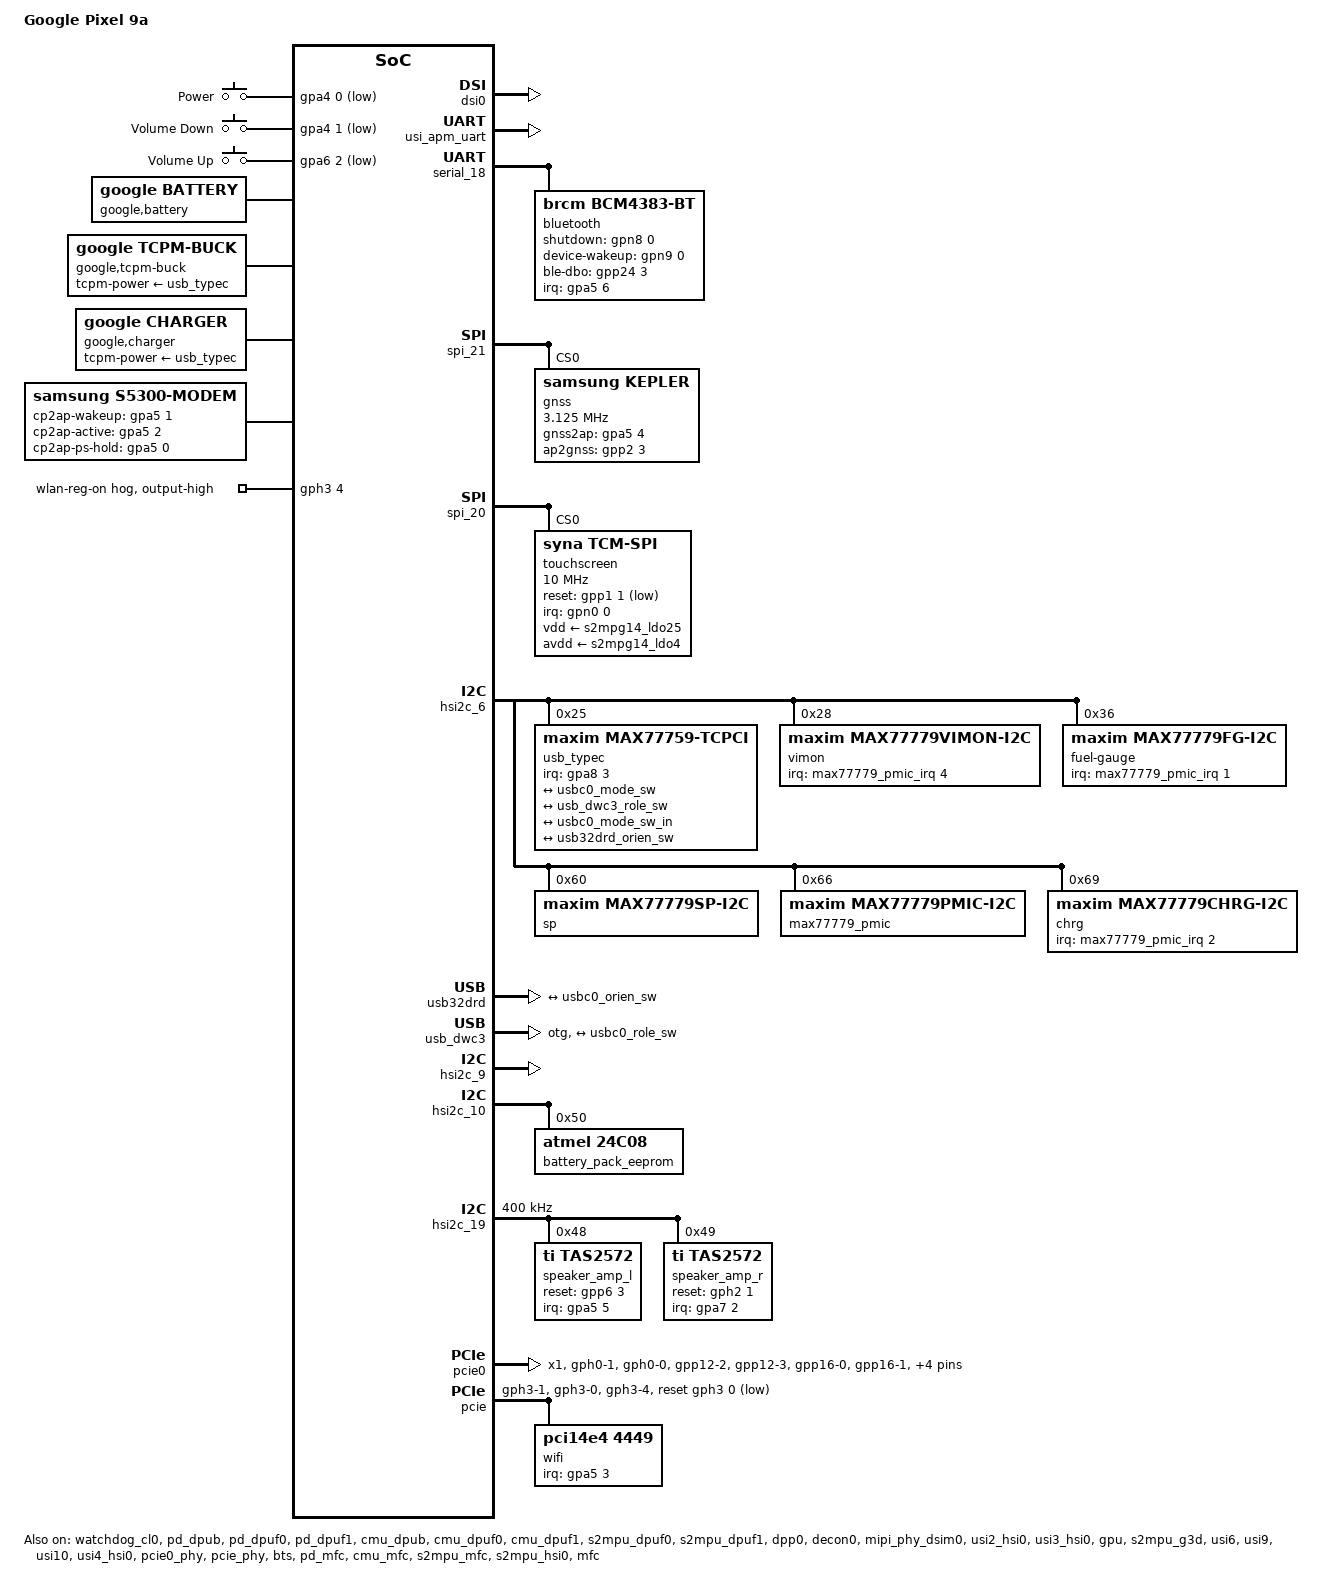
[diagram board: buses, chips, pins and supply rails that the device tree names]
// SPDX-License-Identifier: GPL-2.0-only
/*
 * Google Pixel 9a "Tegu" device tree skeleton.
 *
 * Hardware values are taken from the downstream dump in
 * ../../../../../../research/dumped.dts unless another source is named.
 */

/dts-v1/;

#include <dt-bindings/input/input.h>

#include "zumapro.dtsi"

/ {
	/*
	 * Source: model and downstream compatible strings are from
	 * research/dumped.dts:6-8.  The lowercase compatible follows the
	 * upstream Google Tensor naming convention in google.yaml.
	 */
	model = "Google Pixel 9a";
	compatible = "google,zumapro-tegu", "google,zumapro";

	aliases {
		/*
		 * Source: downstream debug UART alias is uart0/serial_0 at
		 * research/dumped.dts:5772 and 19824.
		 */
		serial0 = &serial_0;
	};

	chosen {
		/*
		 * Source: downstream bootargs select earlycon/console on
		 * 0x10870000 and ttySAC0 at research/dumped.dts:14938-14943.
		 * The empty bootargs property follows GS101 Pixel common DTS because
		 * Pixel bootloaders expect the property to exist.
		 */
		bootargs = "";
		stdout-path = "serial0:115200n8";

		framebuffer0: framebuffer-0 {
			/*
			 * Experimental bootloader framebuffer handoff. Tegu keeps
			 * the bootloader logo lit into Linux, and GS101 Pixel DTSes
			 * use 0xfac00000 for continuous splash simplefb.
			 */
			compatible = "simple-framebuffer";
			memory-region = <&cont_splash_mem>;
			width = <1080>;
			height = <2424>;
			stride = <(1080 * 4)>;
			format = "a8r8g8b8";
			status = "okay";
		};
	};

	/*
	 * Hardware buttons.  All three are plain alive-bank GPIOs with wakeup
	 * EINTs and no PMIC involvement, so they work with just gpio-keys + the
	 * pin mux below.  Source: research/dumped.dts:15219-15245 (gpio_keys)
	 * and the key-power/key-volup/key-voldown pin nodes there: power on
	 * gpa4-0 (pull-up), volume-down on gpa4-1 and volume-up on gpa6-2 (both
	 * pull-none), all in EINT function.  The downstream Android gpio flag
	 * 0x0f is its own encoding; mainline buttons are active-low (pressed =
	 * grounded), matching the in-tree exynos2200-g0s gpio-keys.
	 */
	gpio-keys {
		compatible = "gpio-keys";
		pinctrl-names = "default";
		pinctrl-0 = <&key_power &key_voldown &key_volup>;

		key-power {
			label = "Power";
			linux,code = <KEY_POWER>;
			gpios = <&gpa4 0 GPIO_ACTIVE_LOW>;
			wakeup-source;
		};

		key-voldown {
			label = "Volume Down";
			linux,code = <KEY_VOLUMEDOWN>;
			gpios = <&gpa4 1 GPIO_ACTIVE_LOW>;
			wakeup-source;
		};

		key-volup {
			label = "Volume Up";
			linux,code = <KEY_VOLUMEUP>;
			gpios = <&gpa6 2 GPIO_ACTIVE_LOW>;
			wakeup-source;
		};
	};

	decon_trigger_mask: mmio-init@19470030 {
		/*
		 * Stop the bootloader splash before the DPUF System MMUs
		 * enable translation: mask DECON0's HW trigger (TRIG_CON
		 * HW_TRIG_MASK set, HW_TRIG_EN clear) so the orphaned DPP
		 * fetch goes idle within a frame.  Letting it run into the
		 * empty default domain leaves a stalled fault on DPUF0's AXI
		 * port that wedges the interconnect on the next modeset.
		 * This freezes simplefb/fbcon; mainline owns the panel from
		 * the first modeset on.
		 */
		compatible = "linux,mmio-init-helper";
		reg = <0x0 0x19470030 0x4>;
		mask = <0x11>;
		value = <0x10>;
	};

	/*
	 * Source: RAM banks are from research/dumped.dts:20-32 and 14934-14937.
	 */
	memory@80000000 {
		device_type = "memory";
		reg = <0x0 0x80000000 0x80000000>;
	};

	memory@880000000 {
		device_type = "memory";
		reg = <0x8 0x80000000 0x80000000>;
	};

	memory@900000000 {
		device_type = "memory";
		reg = <0x9 0x00000000 0x80000000>;
	};

	memory@980000000 {
		device_type = "memory";
		reg = <0x9 0x80000000 0x80000000>;
	};

	reserved-memory {
		/*
		 * Source: static reserved-memory ranges are copied from
		 * research/dumped.dts:1292-1517.  Dynamic size-only DMA pools from
		 * the dump are intentionally omitted for this minimal initramfs tree.
		 */
		#address-cells = <2>;
		#size-cells = <1>;
		ranges;

		/*
		 * Leave one 1 MiB firmware slot below 256 MiB. All later MFC
		 * DMA allocations must be above firmware and end within its
		 * 0xf0000000-byte RISC window. This reserves device addresses
		 * only; the DMA allocator supplies the backing pages.
		 */
		mfc_firmware_iova: mfc-firmware-iova {
			iommu-addresses = <&mfc 0x00000000 0x0ff00000>,
					  <&mfc 0xfff00000 0x00100000>;
		};


		/*
		 * Source: ABL fastboot-boot log from 2026-05-24 shows ABL
		 * appends pkvm_guest_firmware@8b000000 before Linux starts.
		 * Keep the downstream range visible here, but do not compile it
		 * while booting through ABL because it overlaps the bootloader
		 * supplied node.
		 */
#if 0
		pkvm_guest_firmware: pkvm-guest-firmware@8b000000 {
			/* Source: research/dumped.dts:1298-1302. */
			reg = <0x0 0x8b000000 0x100000>;
			no-map;
		};
#endif

		ect_reserved: ect@90000000 {
			/* Source: research/dumped.dts:1319-1322. */
			reg = <0x0 0x90000000 0x60000>;
		};

		gsa_reserved: gsa@90200000 {
			/* Source: research/dumped.dts:1325-1328. */
			reg = <0x0 0x90200000 0x3ff000>;
			no-map;
		};

		gsa_reserved_2: gsa@905ff000 {
			/* Source: research/dumped.dts:1331-1334. */
			reg = <0x0 0x905ff000 0x1000>;
			no-map;
		};

		gxp_scratchpad_reserved: gxp-scratchpad@91300000 {
			/* Source: research/dumped.dts:1337-1340. */
			reg = <0x0 0x91300000 0x60000>;
			no-map;
		};

		iif_wait_table_reserved: iif-wait-table@91360000 {
			/* Source: research/dumped.dts:1343-1346. */
			reg = <0x0 0x91360000 0x20000>;
			no-map;
		};

		iif_signal_table_reserved: iif-signal-table@91380000 {
			/* Source: research/dumped.dts:1349-1352. */
			reg = <0x0 0x91380000 0x20000>;
			no-map;
		};

		gxp_secure_data_reserved: gxp-secure-data@91400000 {
			/* Source: research/dumped.dts:1355-1358. */
			reg = <0x0 0x91400000 0x900000>;
			no-map;
		};

		gxp_fw_reserved: gxp-fw@91d00000 {
			/* Source: research/dumped.dts:1361-1364. */
			reg = <0x0 0x91d00000 0x300000>;
			no-map;
		};

		gxp_mcu_fw_reserved: gxp-mcu-fw@92000000 {
			/* Source: research/dumped.dts:1367-1370. */
			reg = <0x0 0x92000000 0x400000>;
			no-map;
		};

		tpu_fw_reserved: tpu-fw@92e00000 {
			/* Source: research/dumped.dts:1373-1376. */
			reg = <0x0 0x92e00000 0x1200000>;
			no-map;
		};

		aoc_reserved: aoc@94000000 {
			/* Source: research/dumped.dts:1379-1382. */
			reg = <0x0 0x94000000 0x3000000>;
			no-map;
		};

		cont_splash_mem: splash@fac00000 {
			/*
			 * Experimental simplefb backing store. 0xfac00000 matches
			 * the GS101 continuous-splash address; no explicit Tegu
			 * downstream reserved-memory node exists in dumped.dts.
			 */
			reg = <0x0 0xfac00000 (1080 * 2424 * 4)>;
			no-map;
		};

		xhci_dma_buffer_reserved: xhci-dma-buffer@17bb5000 {
			/* Source: research/dumped.dts:1508-1512. */
			reg = <0x0 0x17bb5000 0xb000>;
			no-map;
		};

		xhci_dma_reserved: xhci-dma@17bc0000 {
			/* Source: research/dumped.dts:1515-1519. */
			reg = <0x0 0x17bc0000 0x40000>;
			no-map;
		};

		xhci_dma_dram_reserved: xhci-dma-dram@97000000 {
			/* Source: research/dumped.dts:1522-1526. */
			reg = <0x0 0x97000000 0x400000>;
			no-map;
		};

		/*
		 * Source: ABL fastboot-boot log from 2026-05-24 shows ABL
		 * appends sec_dram@b6200000 before Linux starts.  Keep the
		 * downstream range visible here, but do not compile it while
		 * booting through ABL because it overlaps the bootloader supplied
		 * node.
		 */
#if 0
		sec_dram_reserved: sec-dram@b6200000 {
			/* Source: research/dumped.dts:1314-1317. */
			reg = <0x0 0xb6200000 0x9e00000>;
			no-map;
		};
#endif

		seclog_reserved: seclog@c3000000 {
			/* Source: research/dumped.dts:1502-1505. */
			reg = <0x0 0xc3000000 0x80000>;
		};

		header_reserved: header@d8100000 {
			/* Source: research/dumped.dts:1438-1441. */
			reg = <0x0 0xd8100000 0x10000>;
			no-map;
		};

		log_kevents_reserved: log-kevents@d8110000 {
			/* Source: research/dumped.dts:1444-1447. */
			reg = <0x0 0xd8110000 0x700000>;
			no-map;
		};

		log_bcm_reserved: log-bcm@dd610000 {
			/* Source: research/dumped.dts:1450-1454. */
			reg = <0x0 0xdd610000 0x400000>;
			no-map;
		};

		log_s2d_reserved: log-s2d@d8810000 {
			/* Source: research/dumped.dts:1456-1459. */
			reg = <0x0 0xd8810000 0x1800000>;
			no-map;
		};

		log_array_reset_reserved: log-array-reset@da010000 {
			/* Source: research/dumped.dts:1462-1465. */
			reg = <0x0 0xda010000 0xa00000>;
			no-map;
		};

		log_array_panic_reserved: log-array-panic@daa10000 {
			/* Source: research/dumped.dts:1469-1473. */
			reg = <0x0 0xdaa10000 0xa00000>;
			no-map;
		};

		log_slcdump_reserved: log-slcdump@db410000 {
			/* Source: research/dumped.dts:1476-1480. */
			reg = <0x0 0xdb410000 0x1100000>;
			no-map;
		};

		log_preslcdump_reserved: log-preslcdump@dc510000 {
			/* Source: research/dumped.dts:1483-1487. */
			reg = <0x0 0xdc510000 0x1100000>;
			no-map;
		};

		log_itmon_reserved: log-itmon@dda10000 {
			/* Source: research/dumped.dts:1493-1496. */
			reg = <0x0 0xdda10000 0x10000>;
			no-map;
		};

		log_s2d_extract_reserved: log-s2d-extract@dda20000 {
			/* Source: research/dumped.dts:1499-1502. */
			reg = <0x0 0xdda20000 0x600000>;
			no-map;
		};

		/*
		 * Source: ABL fastboot-boot log from 2026-05-24 shows ABL
		 * appends sec_pt@e0000000 before Linux starts.  Keep the
		 * downstream range visible here, but do not compile it while
		 * booting through ABL because it overlaps the bootloader supplied
		 * node.
		 */
#if 0
		sec_pt_reserved: sec-pt@e0000000 {
			/* Source: research/dumped.dts:1309-1312. */
			reg = <0x0 0xe0000000 0x3800000>;
			no-map;
		};
#endif

		cp_rmem_1_reserved: cp-rmem-1@e8000000 {
			/*
			 * Source: research/dumped.dts:1424-1428.  The PKTPROC
			 * DL/UL data rings + buffers; the CP addresses it at
			 * pktproc_cp_base 0x20000000 and self-translates to this
			 * AP-phys before the TLP, so no AP-side window is needed
			 * (docs/subsystems/modem/reference/pktproc-plan.md "Risk #1").  no-map for the
			 * same reason as cp_rmem: the driver maps it non-cached
			 * and the CP DMAs into it (HSI1 IO-coherency is not set
			 * up on mainline).
			 */
			reg = <0x0 0xe8000000 0x2000000>;
			no-map;
		};

		cp_aoc_rmem_reserved: cp-aoc-rmem@197fd000 {
			/* Source: research/dumped.dts:1431-1435. */
			reg = <0x0 0x197fd000 0x3000>;
		};

		cp_rmem_reserved: cp-rmem@ea400000 {
			/*
			 * Source: research/dumped.dts:1410-1414.  no-map so the
			 * modem driver can map it non-cached: the CP reads the
			 * staged boot image and runs the IPC queues in here by
			 * PCIe bus-mastering, and HSI1 IO-coherency is not set
			 * up on mainline.
			 */
			reg = <0x0 0xea400000 0xc00000>;
			no-map;
		};

		cp_msi_rmem_reserved: cp-msi-rmem@f6200000 {
			/*
			 * Source: research/dumped.dts:1417-1421.  no-map for
			 * the same reason: the CP DMA-writes its boot progress
			 * above the MSI termination address in this page.
			 */
			reg = <0x0 0xf6200000 0x1000>;
			no-map;
		};

		abl_reserved: abl@f8800000 {
			/* Source: research/dumped.dts:1304-1307. */
			reg = <0x0 0xf8800000 0x1000000>;
			no-map;
		};

		dss_log_reserved: dss-log@fd3f0000 {
			/* Source: research/dumped.dts:1385-1388. */
			reg = <0x0 0xfd3f0000 0xe000>;
			no-map;
		};

		/*
		 * Source: ABL fastboot-boot log from 2026-05-24 shows ABL
		 * appends debug_kinfo_reserved@fd3fe000 before Linux starts.
		 * Keep the downstream range visible here, but do not compile it
		 * while booting through ABL because it overlaps the bootloader
		 * supplied node.
		 */
#if 0
		debug_kinfo_reserved: debug-kinfo@fd3fe000 {
			/* Source: research/dumped.dts:1391-1394. */
			reg = <0x0 0xfd3fe000 0x1000>;
			no-map;
		};
#endif

		ramoops_reserved: ramoops@fd3ff000 {
			/*
			 * Source: research/dumped.dts:1397-1401, with the pmsg
			 * zone traded for dmesg records.  Downstream splits the
			 * 4 MiB into 2 MiB console + 2 MiB pmsg and carves no
			 * record zone at all, because the pmsg consumer is
			 * Android's logd and its panic post-mortems come from
			 * debug-snapshot; neither exists here, so pmsg would be
			 * 2 MiB that nothing ever reads.  The dmesg zones take
			 * whatever console and pmsg leave (ram.c: dump_mem_sz =
			 * size - console - ftrace - pmsg), hence 8 records here.
			 * Console gets the larger share: a lockup that stops
			 * printing never reaches kmsg_dump, so the console ring
			 * is the only thing that will hold its last moments.
			 */
			compatible = "ramoops";
			reg = <0x0 0xfd3ff000 0x400000>;
			console-size = <0x300000>;
			record-size = <0x20000>;
		};

		bldr_log_reserved: bldr-log@fd800000 {
			/* Source: research/dumped.dts:1404-1407. */
			reg = <0x0 0xfd800000 0x100000>;
			no-map;
		};
	};

	/*
	 * Where GBMS finds the battery pack EEPROM.  gbms_storage locates this
	 * by node name -- of_find_node_by_name(NULL, "google_bms") -- so the
	 * name is the binding and there is no compatible; it reads the pack's
	 * records through the nvmem device named here, which is the ordinary
	 * at24 on i2c-10 (research/dumped.dts:20030).
	 *
	 * Deliberately no "google,lotr-version", matching downstream.  Absent,
	 * the layout version defaults to GBMS_LOTR_DEFAULT (0xff), and
	 * gbms_lotr_update() converts only when the *requested* version is V1 or
	 * V2 -- so the default cannot reach either migration whatever the pack
	 * itself holds.  That matters because both migrations are destructive to
	 * records the Android slot also reads: V1 shifts 900 bytes of history up
	 * by six and zeroes five bytes at 0x5e, V2 writes 0xff over 0x3e2..0x3fe.
	 *
	 * The EEPROM node's "read-only" is a second guard, but not where it
	 * looks: nvmem_device_write() does not consult nvmem->read_only at all.
	 * What refuses the write is at24, which leaves write_max at 0 for a
	 * read-only part, so at24_adjust_write_count() clamps the count to zero
	 * and regmap returns -EINVAL before any byte is sent.  Effective, and
	 * thinner than it sounds -- it rests on regmap rejecting a zero-length
	 * write rather than looping.
	 */
	google_bms {
		nvmem = <&battery_pack_eeprom>;
		nvmem-names = "bms-pack-eeprom";
		google,bee-name = "bms-pack-eeprom";
	};

	/*
	 * The battery layer.  It aggregates the gauge and the charger into the
	 * "battery" power supply userspace sees, runs the multi-tier charge
	 * table below, and is where charge_limit lives.
	 *
	 * The table is the point of the node.  chg-cc-limits is a 6x5 matrix of
	 * percent-of-design-capacity, indexed by the temperature bands in
	 * chg-temp-limits (0/10/20/44/46/48/55 degC) and the float-voltage
	 * tiers in chg-cv-limits (4.20/4.25/4.30/4.35/4.50 V), and scaled by
	 * chg-battery-capacity -- 5000 mAh, which takes priority over the
	 * gauge's 5110 mAh CHARGE_FULL_DESIGN.  So the peak cell, 100% between
	 * 20 and 44 degC below 4.35 V, is 5.0 A, and the coldest and hottest
	 * bands fall to 0.5 A or refuse to charge at all.
	 *
	 * google,eeprom-pairing is deliberately dropped.  It is the one part of
	 * this layer that establishes identity on the pack: when it reads an
	 * unpaired battery it writes an MD5 of the device serial and the pack's
	 * manufacturer record into the pack's DINF tag.  This pack is already
	 * paired, by the Android slot that shares the EEPROM, so the branch
	 * that fires here would be the mismatch one -- and the pairing state is
	 * reported in sysfs and gates no charging decision, so nothing is lost
	 * by not asking.
	 *
	 * What is *not* avoidable is that this node makes the kernel a routine
	 * writer of that shared pack: batt_cycle_count_update() runs from the
	 * battery work loop and stores the SoC-residency bins to BCNT.  That is
	 * the same record, at the same offsets, that the other slot maintains
	 * -- the pack reads as layout v0, which is the layout the driver's
	 * default selects -- so the two agree on where it is, and each keeps
	 * its own tally of the same quantity.
	 */
	google,battery {
		compatible = "google,battery";
		google,fg-psy-name = "max77779fg";

		google,chg-battery-capacity = <0x1388>;
		google,chg-temp-limits = <0x00 0x64 0xc8 0x1b8 0x1cc 0x1e0 0x226>;
		google,chg-cv-limits = <0x401640 0x40d990 0x419ce0 0x426030 0x44aa20>;
		google,chg-cc-limits = <
			0x1e 0x0a 0x0a 0x00 0x00
			0x32 0x1e 0x1e 0x1e 0x1e
			0x64 0x64 0x64 0x64 0x32
			0x5a 0x5a 0x5a 0x5a 0x32
			0x32 0x32 0x32 0x00 0x00
			0x1e 0x00 0x00 0x00 0x00>;
		google,chg-topoff-limits = <0xfa 0xfa 0xfa 0x1f4 0x1f4 0x1f4>;

		google,fv-uv-resolution = <0x2710>;
		google,fv-uv-margin-dpct = <0x401>;
		google,cv-range-accuracy = <0x4e20>;
		google,cv-otv-margin = <0x2ee0>;
		google,cv-debounce-cnt = <0x03>;
		google,cv-tier-ov-cnt = <0x0a>;
		google,cv-tier-switch-cnt = <0x03>;
		google,chg-rest-rate = <0x0f>;
		google,chg-rest-soc = <0x50>;
		google,bd-trickle-recharge-soc = <0x50>;

		/* Time-to-full estimation. */
		google,ttf-temp-idx = <0x02>;
		google,ttf-adapter = <0x1194>;
		google,ttf-soc-table = <0x3f 0x43 0x47 0x4b 0x55 0x5b 0x61 0x64>;
		google,ttf-elap-table = <0x27 0x2a 0x30 0x37 0x49 0x73 0xcb 0x52>;
		google,ttf-tier-table = <0x00 0x3e 0x4b>;
		google,ttf-report-max-ratio = <0x00>;

		/* Battery health: record thresholds and BHI tuning. */
		google,temp-record-thr = <0x12c 0x15e 0x190>;
		google,soc-record-thr = <0x5a 0x5a 0x5f>;
		google,bhi-status-marginal = <0x4f>;
		google,bhi-status-need-rep = <0x4f>;
		google,bhi-cycle-grace = <0x64>;
		google,bhi-algo-ver = <0x03>;

		/*
		 * Age-adjusted charging.  AACR derates the table's capacity by
		 * cycle count and AAFV lowers the float voltage; both read the
		 * cycle count from the pack the other slot has been filling in,
		 * so they start from this battery's real age rather than from
		 * zero.  The aact-* tables are the server-updatable variants --
		 * carried so the node matches downstream, but inert here,
		 * because gbms_init_chg_table() uses them only once something
		 * has actually pushed an update.
		 */
		google,aacr-config = <0x01>;
		google,aafv-config = <0x01>;
		google,aacr-algo = <0x03>;
		google,aacr-cliff-capacity-rate = <0x50>;
		google,aacr-cycle-max = <0x3e8>;
		google,enable-switch-chg-profile;
		google,aact-cv-limits = <0x401640 0x40d990 0x419ce0 0x426030 0x44aa20>;
		google,aact-temp-limits = <0x00 0x64 0xc8 0x1b8 0x1cc 0x1e0 0x226>;
		google,chg-aact-ecc = <0x00 0x12c 0x3e8>;
		google,aact-cc-limits = <
			0x1e 0x0a 0x0a 0x00 0x00
			0x32 0x1e 0x1e 0x1e 0x1e
			0x64 0x64 0x64 0x64 0x32
			0x5a 0x5a 0x5a 0x5a 0x32
			0x32 0x32 0x32 0x00 0x00
			0x1e 0x00 0x00 0x00 0x00
			0x1e 0x0a 0x0a 0x00 0x00
			0x32 0x1e 0x1e 0x1e 0x1e
			0x5f 0x5f 0x5f 0x5f 0x32
			0x5a 0x5a 0x5a 0x5a 0x32
			0x32 0x32 0x32 0x00 0x00
			0x1e 0x00 0x00 0x00 0x00
			0x1e 0x0a 0x0a 0x00 0x00
			0x32 0x1e 0x1e 0x1e 0x1e
			0x5a 0x5a 0x5a 0x5a 0x32
			0x5a 0x5a 0x5a 0x5a 0x32
			0x32 0x32 0x32 0x00 0x00
			0x1e 0x00 0x00 0x00 0x00>;

		/*
		 * Battery virtual sensors.  Both thermal registrations are
		 * non-fatal -- the driver logs and carries on -- so these cost
		 * nothing while no thermal zone references them.
		 */
		google,batt-vs-tz-name = "batt_vs";
		#thermal-sensor-cells = <0x00>;
		#cooling-cells = <0x02>;

		/* Per-cell age references, keyed by the pack's battery ID. */
		google,batt-id-1-atl {
			google,batt-id = <0x01>;
			google,aacr-ref-cycles = <0x257 0x258 0x3e8>;
			google,aacr-ref-fade10 = <0x00 0x64 0x64>;
			google,aafv-ref-cycles = <0xc8 0x190 0x258 0x320 0x3e8 0x3e9>;
			google,aafv-ref-offset = <0x00 0x14 0x28 0x3c 0x50 0x64>;
			google,aacc-chg-temp = <0x00 0x226>;
			google,aacc-chg-weights = <
				0x64 0x64 0x64 0x64 0x64 0x64 0x64 0x64 0x64 0x64
				0x00 0x00 0x00 0x00 0x00 0x00 0x00 0x00 0x00 0x00
				0x00 0x00 0x00 0x00 0x00 0x00 0x00 0x00 0x00 0x00
				0x00 0x00 0x00 0x00 0x00 0x00 0x00 0x00 0x00 0x00
				0x00 0x00 0x00 0x00 0x00 0x00 0x00 0x00 0x00 0x00
				0x00 0x00 0x00 0x00 0x00 0x00 0x00 0x00 0x00 0x00
				0x00 0x00 0x00 0x00 0x00 0x00 0x00 0x00 0x00 0x00
				0x00 0x00 0x00 0x00 0x00 0x00 0x00 0x00 0x00 0x00
				0x00 0x00 0x00 0x00 0x00 0x00 0x00 0x00 0x00 0x00
				0x00 0x00 0x00 0x00 0x00 0x00 0x00 0x00 0x00 0x00>;
		};

		google,batt-id-4-lwn {
			google,batt-id = <0x04>;
			google,aacr-ref-cycles = <0x257 0x258 0x3e8>;
			google,aacr-ref-fade10 = <0x00 0x64 0x64>;
			google,aafv-ref-cycles = <0xc8 0x190 0x258 0x320 0x3e8 0x3e9>;
			google,aafv-ref-offset = <0x00 0x14 0x28 0x3c 0x50 0x64>;
			google,aacc-chg-temp = <0x00 0x226>;
			google,aacc-chg-weights = <
				0x64 0x64 0x64 0x64 0x64 0x64 0x64 0x64 0x64 0x64
				0x00 0x00 0x00 0x00 0x00 0x00 0x00 0x00 0x00 0x00
				0x00 0x00 0x00 0x00 0x00 0x00 0x00 0x00 0x00 0x00
				0x00 0x00 0x00 0x00 0x00 0x00 0x00 0x00 0x00 0x00
				0x00 0x00 0x00 0x00 0x00 0x00 0x00 0x00 0x00 0x00
				0x00 0x00 0x00 0x00 0x00 0x00 0x00 0x00 0x00 0x00
				0x00 0x00 0x00 0x00 0x00 0x00 0x00 0x00 0x00 0x00
				0x00 0x00 0x00 0x00 0x00 0x00 0x00 0x00 0x00 0x00
				0x00 0x00 0x00 0x00 0x00 0x00 0x00 0x00 0x00 0x00
				0x00 0x00 0x00 0x00 0x00 0x00 0x00 0x00 0x00 0x00>;
		};
	};

	/*
	 * The charging policy layer, and the last of the stack.  It runs the
	 * multi CC-CV step charge over google_battery's table, applies the
	 * charge stop and start levels, and owns the battery defender that
	 * pauses charging when the pack sits hot and full.
	 *
	 * Three of the four supplies it names differ from the vendor's, and
	 * each difference removes a layer rather than adding one:
	 *
	 *   - chg-power-supply names the MAX77779 directly rather than "gccd".
	 *     google_ccd exists to present several wired chargers as one, and
	 *     this board describes a single one; the six properties this layer
	 *     asks of a charger -- constant charge current and voltage, the
	 *     termination current, taper control, charging-enabled and the
	 *     GBMS charger state -- are all answered by max77779_charger
	 *     itself.
	 *   - usb-power-supply is omitted entirely rather than pointed at the
	 *     TCPM source supply.  This layer asks a USB supply for PRESENT,
	 *     which TCPM deliberately does not implement -- naming it would
	 *     make every read return -EINVAL, which the caller stores as the
	 *     value, leaving "present" permanently true and the disconnect
	 *     path unreachable.  Left unnamed, the driver substitutes its
	 *     online state, which it reads from the TCPM supply named below
	 *     anyway.  So the vendor's usb_psy.c buys nothing here.
	 *   - wlc-power-supply is omitted with the rest of the wireless
	 *     properties.  The P9222 receiver has no driver here, so nothing
	 *     registers a "wireless" supply; the lookup is optional and the
	 *     pad still charges, because its power reaches the MAX77779's WCIN
	 *     input and is reported by that driver's own "dc" supply.
	 *
	 * tcpm-power-supply stays a phandle to the TCPC, which is how the PPS
	 * code reaches the partner's advertised source capabilities.
	 */
	/*
	 * The buck-mode ballot mainline's Type-C stack does not cast.
	 *
	 * The charger arbitrates its operating mode from the CHARGER_MODE
	 * election, and google_charger's vote asks only for a charge current
	 * -- it never says that an input is attached.  The vote that does is
	 * cast by the vendor's own port controller driver on sink attach, and
	 * this board runs mainline's tcpci_maxim instead, which knows nothing
	 * about it.  Without the ballot the charger resolves to all-off and
	 * switches charging off entirely, so this is not optional.
	 *
	 * It watches the ONLINE property of the supply named here, which is
	 * the sink state TCPM already tracks.
	 */
	google,tcpm-buck {
		compatible = "google,tcpm-buck";
		google,tcpm-power-supply = <&usb_typec>;
	};

	google,charger {
		compatible = "google,charger";
		#cooling-cells = <0x02>;

		google,chg-power-supply = "main-charger";
		google,bat-power-supply = "battery";
		google,tcpm-power-supply = <&usb_typec>;

		google,fv-max-uv = <0x47b760>;
		google,chg-termination-5v;
		google,chg-taper-last-tier;

		/*
		 * Battery defender: stop charging and drain back when the pack
		 * has been hot and near full for long enough, and resume when
		 * it cools or falls back.
		 */
		google,bd-temp-enable;
		google,bd-trigger-time = <0x5460>;
		google,bd-trigger-temp = <0x15e>;
		google,bd-trigger-voltage = <0x4127b0>;
		google,bd-recharge-voltage = <0x40d990>;
		google,bd-drainto-soc = <0x50>;
		google,bd-recharge-soc = <0x4f>;
		google,bd-resume-abs-temp = <0x118>;
		google,bd-resume-soc = <0x32>;
		google,bd-resume-time = <0x3840>;
		google,bd-resume-temp = <0x122>;

		/* Charge-current ceilings for the thermal cooling device. */
		google,thermal-mitigation = <0x4c4b40 0x498c20 0x46cd00 0x440de0
			0x414ec0 0x3e8fa0 0x3bd080 0x391160 0x365240 0x339320
			0x30d400 0x2e14e0 0x2b55c0 0x2896a0 0x25d780 0x231860
			0x205940 0x1d9a20 0x1adb00 0x181be0 0x155cc0 0x129da0
			0xfde80 0xd1f60 0xa6040 0x7a120>;
		google,thermal-mitigation-budgets = <0x389c30 0x367d38 0x348938
			0x324ee8 0x303f90 0x2e6300 0x2c8670 0x2ae090 0x293e98
			0x27a470 0x260a48 0x238d90 0x2191c0 0x1fbd00 0x1e0780
			0x1c7528 0x1b0210 0x19b220 0x185678 0x16fad0 0x1608a0
			0x151670 0x149d58 0x142440 0x136ca8 0x12b128>;
		google,thermal-stats-lvl-map = <0x00 0x02 0x05 0x08 0x0b>;
	};
};

&watchdog_cl0 {
	/*
	 * Source: downstream enables watchdog_cl0 implicitly in
	 * research/dumped.dts:15248-15257.  Cluster 1 remains disabled until the
	 * downstream use_multistage_wdt behavior at dumped.dts:15268 is modeled.
	 */
	status = "okay";
};

&pd_dpub {
	status = "okay";
};

&pd_dpuf0 {
	status = "okay";
};

&pd_dpuf1 {
	status = "okay";
};

&cmu_dpub {
	status = "okay";
};

&cmu_dpuf0 {
	status = "okay";
};

&cmu_dpuf1 {
	status = "okay";
};

/*
 * DPU fetch path: framebuffer scanout through DPP0 with the DPUF System MMUs
 * translating.  The always-on display power domains must be enabled so the
 * SysMMU single-domain auto-attach can find its provider.
 *
 * Enabling translation orphans the bootloader splash: its DPP fetch faults
 * against the empty default domain as soon as DECON probes.  The first
 * mainline modeset stops and reprograms the pipeline anyway.
 */
&pd_dpub {
	status = "okay";
};

&pd_dpuf0 {
	status = "okay";
};

&pd_dpuf1 {
	status = "okay";
};

&iommu_group_dpu {
	status = "okay";
};

/* Reopened on every DPUF domain power-on, before its System MMU resumes. */
&s2mpu_dpuf0 {
	status = "okay";
};

&s2mpu_dpuf1 {
	status = "okay";
};

&sysmmu_dpuf0 {
	status = "okay";
};

&sysmmu_dpuf1 {
	status = "okay";
};

&dpp0 {
	status = "okay";
};

&decon0 {
	status = "okay";
};

/*
 * Transmit-side probe.  Keep this before enabling real scanout: DSIM/DPHY/panel
 * may bind and attach, but link/PHY programming should remain gated on DRM
 * bridge enable or host transfers.
 */
&sysreg_dpub {
	status = "okay";
};

&mipi_phy_dsim0 {
	status = "okay";
};

&dsi0 {
	status = "okay";

	panel@0 {
		status = "okay";
	};
};

/*
 * S2MPG14 main PMIC, reached over ACPM IPC channel 2 with PMIC select 0.
 * Source: downstream zuma-pmic.dtsi s2mpg14mfd (acpm-ipc-channel = <2>,
 * acpm-speedy-channel = <0>, IRQ = INTCOMB_VGPIO2AP_ALIVE = GIC SPI 74).
 * The interrupt is the APM vGPIO combiner output; the mainline driver
 * does not request it yet (no combiner driver), it only has to resolve.
 *
 * Only the touchscreen rails are described, and deliberately WITHOUT
 * voltage constraints: the driver is enable-only, the bootloader leaves
 * the voltage selectors at the correct values (L4M reads 0x3c, L25M 0x2c
 * before the downstream kernel touches them), and the downstream kernel
 * also only ever flips the enable bit (UPDATE val=0x80 mask=0x80) —
 * hardware-verified in research/tracing/acpm-boot-rail-snapshot.md.
 * Downstream constraints, for reference only: L4M 2.5-3.3 V (TS1_AVDD),
 * L25M 1.6-1.95 V (TS1_DVDD).  Keep new rails equally minimal; a wrong
 * voltage constraint here is the one thing that can genuinely damage
 * hardware.
 */
&acpm_ipc {
	pmic {
		compatible = "samsung,s2mpg14-pmic";
		/*
		 * The PMIC has no interrupt wire: it raises an in-band I3C
		 * interrupt which the APM forwards through the vGPIO-to-AP
		 * combiner, and the combiner drives this GIC line.
		 */
		interrupts = <GIC_SPI 74 IRQ_TYPE_LEVEL_HIGH 0>;
		samsung,vgpio2ap-syscon = <&sysreg_vgpio2ap>;
		wakeup-source;

		regulators {
			s2mpg14_ldo4: ldo4m {
				regulator-name = "L4M_TS1_AVDD";
			};

			s2mpg14_ldo25: ldo25m {
				regulator-name = "L25M_TS1_DVDD";
			};
		};

		/*
		 * On-device power metering, read-only.  Channel -> rail mux is
		 * the authoritative tegu ODPM assignment from
		 * research/dumped.dts (mux codes are the S2MPG14 muxsel values,
		 * BUCK1..9 = 0x01..0x09).  Channels 0-8 are the internal buck
		 * rails; 9-11 are the external (VSEN) rails (schematic
		 * VSYS_PWR_DISPLAY/CAMERA/RFFE) sensed across an off-chip shunt.
		 */
		meter {
			compatible = "samsung,s2mpg14-meter";
			#address-cells = <1>;
			#size-cells = <0>;

			channel@0 {
				reg = <0>;
				samsung,muxsel = <0x01>;
				label = "VDD_MIF";
			};
			channel@1 {
				reg = <1>;
				samsung,muxsel = <0x02>;
				label = "VDD_CPUCL1_MID";
			};
			channel@2 {
				reg = <2>;
				samsung,muxsel = <0x03>;
				label = "VDD_CPUCL2_BIG";
			};
			channel@3 {
				reg = <3>;
				samsung,muxsel = <0x04>;
				label = "VDD_CPUCL0_LITTLE";
			};
			channel@4 {
				reg = <4>;
				samsung,muxsel = <0x05>;
				label = "VDD_INT";
			};
			channel@5 {
				reg = <5>;
				samsung,muxsel = <0x06>;
				label = "LLDO1";
			};
			channel@6 {
				reg = <6>;
				samsung,muxsel = <0x07>;
				label = "VDD_TPU";
			};
			channel@7 {
				reg = <7>;
				samsung,muxsel = <0x08>;
				label = "LLDO2";
			};
			channel@8 {
				reg = <8>;
				samsung,muxsel = <0x09>;
				label = "VDD_CPUCL1_M";
			};

			/* External (VSEN) rails: VSYS drop across an off-chip shunt. */
			channel@9 {
				reg = <9>;
				samsung,muxsel = <0x5c>;
				shunt-resistor-micro-ohms = <5000>;
				label = "VSYS_PWR_DISPLAY";
			};
			channel@10 {
				reg = <10>;
				samsung,muxsel = <0x5d>;
				shunt-resistor-micro-ohms = <5000>;
				label = "VSYS_PWR_CAMERA";
			};
			channel@11 {
				reg = <11>;
				samsung,muxsel = <0x5e>;
				shunt-resistor-micro-ohms = <5000>;
				label = "VSYS_PWR_RFFE";
			};
		};
	};
};

/*
 * S2MPG15 sub PMIC, reached over ACPM IPC channel 2 with PMIC select 1
 * (mirroring the s2mpg10/s2mpg11 main/sub pair).  Source: downstream
 * zuma-pmic.dtsi s2mpg15mfd (acpm-speedy-channel = <1>).  Only the
 * read-only ODPM power meter is described; no regulators are claimed.
 *
 * Channel -> rail mux follows the tegu ODPM assignment from
 * research/dumped.dts.  Internal rails use the S2MPG15 muxsel values
 * (BUCKnS = 0x0n, LDOnS = 0x20 + n); two external rails (MODEM, WLAN-BT)
 * measure the VSYS drop across an off-chip shunt (muxsel 0x5c-0x5d) and
 * carry the shunt value so the driver can scale them.  Channel 11 is the
 * VSEN_C6/mmWave slot downstream, but the Pixel 9a has no mmWave, so it
 * is mapped to S12S_VDD_AUR (BUCK12S) -- the live rail the downstream
 * kernel meters there on this board.  Labels are the downstream
 * schematic rail names.
 */
&acpm_ipc {
	pmic-sub {
		compatible = "samsung,s2mpg15-pmic";

		/*
		 * The two sensor rails the AoC powers.  Enable-only (bit 7 of
		 * LxS_CTRL); the bootloader leaves the voltage selectors at the
		 * downstream values so no voltage constraint is claimed -- see
		 * s2mps11.c s2mpg15_regulators.  Consumed by the aoc node's
		 * sensor_power_list below.
		 */
		regulators {
			s2mpg15_ldo5: ldo5s {
				regulator-name = "L5S_PROX";
			};

			s2mpg15_ldo7: ldo7s {
				regulator-name = "L7S_SENSORS";
			};

			/*
			 * The under-display fingerprint sensor's 3.3 V supply.
			 *
			 * The PMIC table calls it "SPARE" and nothing in the
			 * device tree consumes it, downstream included -- the
			 * only thing that claims it is the Goodix overlay
			 * zumapro-tegu-udfps.dtsi, whose entire content is the
			 * goodixfp node, its IRQ and reset pins, and forcing
			 * this rail always-on at 3.3 V.  So always-on here too,
			 * rather than a consumer reference: there is no
			 * mainline driver to hang one off, and the sensor is
			 * driven from userspace over the Trusty TA.
			 *
			 * Enable-only, like the two rails above: the selector
			 * already reads 3300 mV with the rail disabled, so
			 * claiming a voltage constraint would only invite the
			 * core to program one.
			 */
			s2mpg15_ldo15: ldo15s {
				regulator-name = "L15S_SPARE";
				regulator-always-on;
			};
		};

		meter {
			compatible = "samsung,s2mpg15-meter";
			#address-cells = <1>;
			#size-cells = <0>;

			channel@0 {
				reg = <0>;
				samsung,muxsel = <0x01>;
				label = "S1S_VDD_CAM";
			};
			channel@1 {
				reg = <1>;
				samsung,muxsel = <0x02>;
				label = "S2S_VDD_G3D";
			};
			channel@2 {
				reg = <2>;
				samsung,muxsel = <0x04>;
				label = "S4S_VDD2H_MEM";
			};
			channel@3 {
				reg = <3>;
				samsung,muxsel = <0x05>;
				label = "S5S_VDDQ_MEM";
			};
			channel@4 {
				reg = <4>;
				samsung,muxsel = <0x36>;
				label = "L22S_UDFPS";
			};
			channel@5 {
				reg = <5>;
				samsung,muxsel = <0x09>;
				label = "S9S_VDD_AOC";
			};
			channel@6 {
				reg = <6>;
				samsung,muxsel = <0x22>;
				label = "L2S_PLL_MIPI_UFS";
			};
			channel@7 {
				reg = <7>;
				samsung,muxsel = <0x03>;
				label = "S3S_LLDO1";
			};
			channel@8 {
				reg = <8>;
				samsung,muxsel = <0x35>;
				label = "L21S_VDD2L_MEM";
			};
			channel@9 {
				reg = <9>;
				samsung,muxsel = <0x5c>;
				shunt-resistor-micro-ohms = <5000>;
				label = "VSYS_PWR_MODEM";
			};
			channel@10 {
				reg = <10>;
				samsung,muxsel = <0x5d>;
				shunt-resistor-micro-ohms = <10000>;
				label = "VSYS_PWR_WLAN_BT";
			};
			channel@11 {
				reg = <11>;
				samsung,muxsel = <0x0c>;
				label = "S12S_VDD_AUR";
			};
		};
	};
};

/*
 * Give the AoC its sensor rails.  The AoC driver enables sensor_power_list
 * at init (reset_sensor_power); without them the AoC sensor stack has no
 * power and enumerates only fused/software sensors -- the physical
 * LSM6DSV/MMC5616/SPL07003/TMD3733 chips never probe.  sensor_1v8 =
 * L7S_SENSORS (LDO7S, 1.8 V), sensor_3v3 = L5S_PROX (LDO5S, 3.3 V); matches
 * downstream aoc@17000000 in research/dumped.dts.
 */
&aoc {
	sensor_1v8-supply = <&s2mpg15_ldo7>;
	sensor_3v3-supply = <&s2mpg15_ldo5>;
	sensor_power_list = "sensor_1v8", "sensor_3v3";
};

/*
 * Touchscreen: Synaptics TouchComm on BLK_HSI0 USI2 SPI, CS0, 10 MHz.
 * Wiring is from the downstream zuma-tegu-common-touch.dtsi and
 * research/dumped.dts touchscreen@0: IRQ gpn0-0 (active-low, custom-alive
 * EINT bank), reset gpp1-1 (active-low), rails S2MPG14 m_ldo25 (vdd,
 * 1.8 V, L25M_TSP_DVDD) and m_ldo4 (avdd, 3.3 V, L4M_TS_AVDD).
 *
 * The SPI bus pins keep their bootloader mux: downstream ships an empty
 * pinctrl-0 on this bus, so nothing disturbs them (same adoption approach
 * as the display pipeline).  pinctrl_hsi0 is enabled further down for the
 * modem PCIe and speaker-amp pins, but no node touches the SPI bus mux.
 *
 * HW boot 2026-06-12 confirmed the rails are off after ABL (probe ran,
 * SPI transferred, IDENTIFY read all-zero), so they are wired to the
 * real s2mpg14 LDOs above and the driver powers them up itself.
 */
&pinctrl_eint {
	ts_irq: ts-irq-pins {
		samsung,pins = "gpn0-0";
		samsung,pin-pud = <ZUMAPRO_PIN_PULL_NONE>;
		samsung,pin-drv = <ZUMAPRO_PIN_DRV_X1>;
	};

	/* BT_REG_ON: BCM4383 Bluetooth power enable (output). */
	bt_reg_on: bt-reg-on-pins {
		samsung,pins = "gpn8-0";
		samsung,pin-function = <ZUMAPRO_PIN_FUNC_OUTPUT>;
		samsung,pin-pud = <ZUMAPRO_PIN_PULL_NONE>;
	};

	/* BT_DEV_WAKE: host->device wake (output). */
	bt_dev_wake: bt-dev-wake-pins {
		samsung,pins = "gpn9-0";
		samsung,pin-function = <ZUMAPRO_PIN_FUNC_OUTPUT>;
		samsung,pin-pud = <ZUMAPRO_PIN_PULL_NONE>;
	};
};

&pinctrl_peric0 {
	ts_reset: ts-reset-pins {
		samsung,pins = "gpp1-1";
		samsung,pin-pud = <ZUMAPRO_PIN_PULL_NONE>;
		samsung,pin-drv = <ZUMAPRO_PIN_DRV_X1>;
	};

	/* Left speaker amp reset (downstream tas2572_1_rst). */
	spk_amp_l_rst: spk-amp-l-rst-pins {
		samsung,pins = "gpp6-3";
		samsung,pin-function = <ZUMAPRO_PIN_FUNC_OUTPUT>;
		samsung,pin-pud = <ZUMAPRO_PIN_PULL_NONE>;
	};

	/*
	 * CP power/reset and AP-status outputs.  Downstream programs every one
	 * to retain its previous output level in powerdown; the bootloader leaves
	 * their CON_PDN fields at input, which can drop the CP rails in SYS_SLEEP.
	 */
	modem_ap2cp_ctrl: modem-ap2cp-ctrl-pins {
		samsung,pins = "gpp12-2", "gpp12-3", "gpp16-0",
			       "gpp16-1", "gpp16-2",
			       "gpp16-3";
		samsung,pin-pud = <ZUMAPRO_PIN_PULL_NONE>;
		samsung,pin-con-pdn = <ZUMAPRO_PIN_CON_PDN_PREV>;
		samsung,pin-pud-pdn = <ZUMAPRO_PIN_PULL_NONE>;
	};

	modem_ap2cp_pm_wrst: modem-ap2cp-pm-wrst-pins {
		samsung,pins = "gpp8-3";
		samsung,pin-function = <ZUMAPRO_PIN_FUNC_OUTPUT>;
		samsung,pin-pud = <ZUMAPRO_PIN_PULL_NONE>;
		samsung,pin-con-pdn = <ZUMAPRO_PIN_CON_PDN_PREV>;
		samsung,pin-pud-pdn = <ZUMAPRO_PIN_PULL_NONE>;
	};
};

&pinctrl_peric1 {
	/*
	 * BT_BLE_DBO (gpp24-3): clock for the external flip-flop that gates the
	 * BCM4383's BT_REG_ON.  hci_bcm pulses it after each REG_ON change so
	 * the chip actually sees the new power state.  Driven as an output.
	 */
	bt_ble_dbo: bt-ble-dbo-pins {
		samsung,pins = "gpp24-3";
		samsung,pin-function = <ZUMAPRO_PIN_FUNC_OUTPUT>;
		samsung,pin-pud = <ZUMAPRO_PIN_PULL_NONE>;
	};
};

/*
 * Button pin mux.  Function EINT (0xf) and the pulls match the downstream
 * key-power/key-voldown/key-volup nodes exactly (power pulls up, the volume
 * keys float).  Requesting the wakeup EINT on each gpio-keys gpio drives the
 * interrupt; the static EINT mux here mirrors the in-tree exynos2200-g0s board.
 */
&pinctrl_alive {
	key_power: key-power-pins {
		samsung,pins = "gpa4-0";
		samsung,pin-function = <ZUMAPRO_PIN_FUNC_EINT>;
		samsung,pin-pud = <ZUMAPRO_PIN_PULL_UP>;
		samsung,pin-drv = <ZUMAPRO_PIN_DRV_X1>;
	};

	key_voldown: key-voldown-pins {
		samsung,pins = "gpa4-1";
		samsung,pin-function = <ZUMAPRO_PIN_FUNC_EINT>;
		samsung,pin-pud = <ZUMAPRO_PIN_PULL_NONE>;
		samsung,pin-drv = <ZUMAPRO_PIN_DRV_X1>;
	};

	key_volup: key-volup-pins {
		samsung,pins = "gpa6-2";
		samsung,pin-function = <ZUMAPRO_PIN_FUNC_EINT>;
		samsung,pin-pud = <ZUMAPRO_PIN_PULL_NONE>;
		samsung,pin-drv = <ZUMAPRO_PIN_DRV_X1>;
	};

	modem_cp2ap_wrst: modem-cp2ap-wrst-pins {
		samsung,pins = "gpa7-3";
		samsung,pin-function = <ZUMAPRO_PIN_FUNC_INPUT>;
		samsung,pin-pud = <ZUMAPRO_PIN_PULL_DOWN>;
	};

	/* MAX77759 USB Type-C interrupt (downstream usb-pd-irq). */
	usb_pd_irq: usb-pd-irq-pins {
		samsung,pins = "gpa8-3";
		samsung,pin-function = <ZUMAPRO_PIN_FUNC_EINT>;
		samsung,pin-pud = <ZUMAPRO_PIN_PULL_UP>;
		samsung,pin-drv = <ZUMAPRO_PIN_DRV_X1>;
	};

	/* MAX77779 IF-PMIC interrupt (downstream if-pmic-irq). */
	if_pmic_irq: if-pmic-irq-pins {
		samsung,pins = "gpa8-0";
		samsung,pin-function = <ZUMAPRO_PIN_FUNC_EINT>;
		samsung,pin-pud = <ZUMAPRO_PIN_PULL_UP>;
		samsung,pin-drv = <ZUMAPRO_PIN_DRV_X1>;
	};

	/* Right speaker amp IRQ, XEINT_16 (downstream tas2572_2_irq). */
	spk_amp_r_irq: spk-amp-r-irq-pins {
		samsung,pins = "gpa7-2";
		samsung,pin-function = <ZUMAPRO_PIN_FUNC_EINT>;
		samsung,pin-pud = <ZUMAPRO_PIN_PULL_UP>;
		samsung,pin-drv = <ZUMAPRO_PIN_DRV_X1>;
	};
};

/* Left speaker amp IRQ, XEINT_5 (downstream tas2572_1_irq). */
&pinctrl_far_alive {
	modem_cp2ap_ps_hold: modem-cp2ap-ps-hold-pins {
		samsung,pins = "gpa5-0";
		samsung,pin-function = <ZUMAPRO_PIN_FUNC_INPUT>;
		samsung,pin-pud = <ZUMAPRO_PIN_PULL_NONE>;
	};

	modem_cp2ap_wakeup: modem-cp2ap-wakeup-pins {
		samsung,pins = "gpa5-1";
		samsung,pin-function = <ZUMAPRO_PIN_FUNC_EINT>;
		samsung,pin-pud = <ZUMAPRO_PIN_PULL_DOWN>;
	};

	modem_cp2ap_active: modem-cp2ap-active-pins {
		samsung,pins = "gpa5-2";
		samsung,pin-function = <ZUMAPRO_PIN_FUNC_EINT>;
		samsung,pin-pud = <ZUMAPRO_PIN_PULL_NONE>;
	};

	spk_amp_l_irq: spk-amp-l-irq-pins {
		samsung,pins = "gpa5-5";
		samsung,pin-function = <ZUMAPRO_PIN_FUNC_EINT>;
		samsung,pin-pud = <ZUMAPRO_PIN_PULL_UP>;
		samsung,pin-drv = <ZUMAPRO_PIN_DRV_X1>;
	};

	wlan_host_wake: wlan-host-wake-pins {
		samsung,pins = "gpa5-3";
		samsung,pin-function = <ZUMAPRO_PIN_FUNC_EINT>;
		samsung,pin-pud = <ZUMAPRO_PIN_PULL_DOWN>;
		samsung,pin-drv = <ZUMAPRO_PIN_DRV_X1>;
	};

	/* BT_HOST_WAKE: device->host wake EINT (gpa5-6, pull-down). */
	bt_host_wake: bt-host-wake-pins {
		samsung,pins = "gpa5-6";
		samsung,pin-function = <ZUMAPRO_PIN_FUNC_EINT>;
		samsung,pin-pud = <ZUMAPRO_PIN_PULL_DOWN>;
		samsung,pin-drv = <ZUMAPRO_PIN_DRV_X1>;
	};
};

/*
 * BCM4383 Bluetooth.  The same combo chip as WiFi (which is the brcmfmac
 * side over PCIe); Bluetooth is the separate UART interface on the always-on
 * APM USI1 UART (uart18, added in zumapro.dtsi).  The REG_ON / dev-wake
 * outputs and the gpa5-6 host-wake EINT are from research/dumped.dts btbcm
 * (the downstream goog,nitrous sideband node) and match the live dump.  The
 * host driver is mainline hci_bcm over serdev; the Google nitrous driver is
 * not ported.  Patchram firmware is brcm/BCM.hcd (btbcm derives exactly that
 * name for this UART chip).  No local-bd-address: the per-device BD_ADDR
 * lives in the vendor cfg partition, not in the SoC, so it is left to
 * firmware / runtime provisioning rather than hardcoded here.
 */
&usi_apm_uart {
	/*
	 * clkreq-on keeps the ALIVE-block USI clock continuously fed so the
	 * UART receiver can clock in the BCM4383's replies.  Without it HWACG
	 * gates the RX clock when the bus is idle: the controller still
	 * transmits (host-driven) but never receives, so the chip looks mute.
	 */
	samsung,clkreq-on; /* needed for UART mode */
	status = "okay";
};

&serial_18 {
	status = "okay";

	bluetooth {
		compatible = "brcm,bcm4383-bt";
		shutdown-gpios = <&gpn8 0 GPIO_ACTIVE_HIGH>;
		device-wakeup-gpios = <&gpn9 0 GPIO_ACTIVE_HIGH>;
		interrupts-extended = <&gpa5 6 IRQ_TYPE_EDGE_RISING>;
		interrupt-names = "host-wakeup";
		ble-dbo-gpios = <&gpp24 3 GPIO_ACTIVE_HIGH>;
		max-speed = <3000000>;
		pinctrl-names = "default";
		pinctrl-0 = <&bt_reg_on &bt_dev_wake &bt_host_wake &bt_ble_dbo>;
	};
};

&usi2_hsi0 {
	samsung,mode = <USI_MODE_SPI>;
	status = "okay";
};

/* USI3_HSI0 in SPI mode: the bus the KEPLER GNSS receiver hangs off. */
&usi3_hsi0 {
	samsung,mode = <USI_MODE_SPI>;
	status = "okay";
};

&spi_21 {
	status = "okay";

	/*
	 * Source: research/dumped.dts -- gnss@0 under spi@111E0000
	 * (spi-max-frequency 0x2faf08), with the handshake lines from the
	 * gnssif node (gpio_gnss2ap_spi gpa5-4, gpio_ap2gnss_spi gpp2-3) and
	 * their pin configuration from the gnss_spi_irq and gnss_spi_int
	 * pinctrl groups.
	 *
	 * Both lines are active high here even though the downstream cells set
	 * the active-low flag: downstream never consults it, reading the line
	 * with raw gpio_get_value() and requesting IRQF_TRIGGER_HIGH, so
	 * active high is what reproduces the behaviour the hardware has.
	 * gnss2ap idles low, which the downstream pinctrl agrees with -- it
	 * gives that pin a pull-down.
	 */
	gnss@0 {
		compatible = "samsung,kepler";
		reg = <0>;
		spi-max-frequency = <3125000>;
		gnss2ap-gpios = <&gpa5 4 GPIO_ACTIVE_HIGH>;
		ap2gnss-gpios = <&gpp2 3 GPIO_ACTIVE_HIGH>;
	};
};

&spi_20 {
	status = "okay";

	touchscreen@0 {
		compatible = "syna,tcm-spi";
		reg = <0>;
		spi-max-frequency = <10000000>;
		spi-cs-setup-delay-ns = <2000>;

		interrupts-extended = <&gpn0 0 IRQ_TYPE_LEVEL_LOW>;
		reset-gpios = <&gpp1 1 GPIO_ACTIVE_LOW>;

		pinctrl-names = "default";
		pinctrl-0 = <&ts_irq &ts_reset>;

		vdd-supply = <&s2mpg14_ldo25>;
		avdd-supply = <&s2mpg14_ldo4>;

		/*
		 * Opt in to the Touch Bus Negotiator: while the display is off
		 * the driver puts the IC into low-power gesture mode and hands
		 * the SPI bus to AoC (see the /tbn node), so AoC can watch for a
		 * tap and wake the AP over its mailbox.  Without this the driver
		 * uses the plain deep-sleep path and owns the bus throughout.
		 *
		 * The handoff follows the panel: AoC has to own the bus for the
		 * whole time the screen is dark, which starts when the panel is
		 * unprepared and not when the AP later suspends.
		 */
		panel = <&panel>;
		goog,tbn-enabled;
	};
};

/*
 * GPU.  The bootloader hands it over powered; panthor adopts that state and
 * reads the ACPM idle clocks (core/G3DL2 160 MHz, stacks/G3D 150 MHz), and
 * the G3D domains follow its runtime PM from then on.  Requires the CSF
 * firmware staged in the rootfs at
 * /lib/firmware/arm/mali/arch11.8/mali_csffw.bin -- without it panthor
 * probes but bails at firmware load.  The "google,zumapro-mali" compatible
 * makes panthor program the zumapro L2 slice (ASN) hash before L2 power-up;
 * without it the GPU's DRAM accesses (including its own MMU page-table walks)
 * decode to the wrong channel and bus-fault, and the MCU never boots.
 *
 * The S2MPU in the GPU's block resets to blocking with the domain; the GPU
 * links to it and will not probe without it.
 */
&gpu {
	status = "okay";
};

&s2mpu_g3d {
	status = "okay";
};

/*
 * MAX77779 ModelGauge m5 fuel gauge on the PMIC I2C bus (USI6/PERIC0).  The
 * gauge tracks state-of-charge autonomously and this driver only reads it, so
 * no battery model is programmed and no rail is touched.  The interrupt lives
 * on the MAX77779 PMIC core described below at 0x66 rather than on a SoC GPIO;
 * this driver does not use it, so the node carries no interrupt and it polls.
 * The 2 mOhm sense resistor matches the downstream default
 * (max77779,rsense-default of 200 in 10-uOhm units) and the tegu battery model
 * files (BC79_TG4_2mOhm_*), and scales the current and charge readings.
 */
&usi6 {
	samsung,mode = <USI_MODE_I2C>;
	status = "okay";
};

&hsi2c_6 {
	status = "okay";

	/*
	 * MAX77759 TCPC at the downstream address and gpa8-3 interrupt.  Keep
	 * this first event-path port sink/device-only with PD disabled: source,
	 * charging and regulator control remain deliberately out of scope.
	 */
	usb_typec: usb-typec@25 {
		compatible = "maxim,max77759-tcpci", "maxim,max33359";
		reg = <0x25>;
		interrupts-extended = <&gpa8 3 IRQ_TYPE_LEVEL_LOW>;
		pinctrl-0 = <&usb_pd_irq>;
		pinctrl-names = "default";

		/*
		 * The vendor D+/D- switch is inside this TCPC, so the connector
		 * links its mode switch back to the parent node.
		 */
		mode-switch;

		port {
			usbc0_mode_sw_in: endpoint {
				remote-endpoint = <&usbc0_mode_sw>;
			};
		};

		connector {
			compatible = "usb-c-connector";
			label = "USB-C";
			data-role = "device";
			power-role = "sink";
			self-powered;
			pd-disable;
			typec-power-opmode = "default";

			ports {
				#address-cells = <1>;
				#size-cells = <0>;

				/* High speed: the DWC3 data role, and the */
				/* vendor D+/D- switch inside this TCPC.  */
				port@0 {
					reg = <0>;
					#address-cells = <1>;
					#size-cells = <0>;

					usbc0_role_sw: endpoint@0 {
						reg = <0>;
						remote-endpoint = <&usb_dwc3_role_sw>;
					};

					usbc0_mode_sw: endpoint@1 {
						reg = <1>;
						remote-endpoint = <&usbc0_mode_sw_in>;
					};
				};

				/* Super speed: the USB32DRD combo PHY, which */
				/* takes the connector orientation.           */
				port@1 {
					reg = <1>;

					usbc0_orien_sw: endpoint {
						remote-endpoint = <&usb32drd_orien_sw>;
					};
				};
			};
		};
	};

	/*
	 * The MAX77779's battery voltage/current monitor.  It captures 64
	 * synchronised pack voltage and current samples into a buffer inside
	 * the part, which the driver then reads back over i2c.  Measurement
	 * only: everything the driver programs is a sample-count and
	 * stop-condition word, a one-bit enable, a trigger-source select and a
	 * one-bit interrupt mask, and none of it drives anything.  The block
	 * also has comparison thresholds the driver never writes.
	 *
	 * Nothing in this tree consumes the samples.  The gauge does not --
	 * neither this one nor downstream's mentions the monitor -- and the
	 * two consumers that do, the battery current limiter and the MAX77779
	 * firmware updater, are not ported.  So the block captures nothing:
	 * bvim_trig selects which events start a capture, the driver derives
	 * that register from the trigger masks of registered clients, and with
	 * none registered it stays 0.  BVIM_CTRL's arm bit is not a second way
	 * in; the hardware clears it when a capture ends and the driver
	 * re-arms it, so setting it while it is already set does nothing.
	 *
	 * It is described now because it is the second consumer of the PMIC
	 * interrupt cascade and the first one whose interrupt can be raised on
	 * demand: a gauge interrupts only on an alert, so the gauge's
	 * registration on that cascade does not exercise delivery through it.
	 * A capture raises BVIM_Samples_Rdy one buffer later, which is what
	 * turns the cascade from registered into delivering.
	 *
	 * The vendor device tree also gives this node max77779,pmic and
	 * max77779,psy-type-unknown.  Both are dropped: this driver reads
	 * neither property, and it registers no power supply for the second
	 * one to apply to.
	 */
	vimon@28 {
		compatible = "maxim,max77779vimon-i2c";
		reg = <0x28>;
		interrupt-parent = <&max77779_pmic_irq>;
		interrupts = <4 IRQ_TYPE_LEVEL_LOW>;
	};

	fuel-gauge@36 {
		compatible = "maxim,max77779fg-i2c";
		reg = <0x36>;
		interrupt-parent = <&max77779_pmic_irq>;
		interrupts = <1 IRQ_TYPE_LEVEL_LOW>;
		max77779,pmic = <&max77779_pmic>;

		/*
		 * The gauge stops presenting itself as a battery now that
		 * google_battery is described: that layer registers the
		 * "battery" power supply userspace consumes, and the gauge
		 * becomes the raw source it reads.  Two drivers claiming
		 * POWER_SUPPLY_TYPE_BATTERY would leave which one UPower picks
		 * to enumeration order, so this property makes the gauge
		 * declare UNKNOWN and the question does not arise.  It belongs
		 * with google_battery and not a step earlier -- on its own it
		 * would have taken the battery away from userspace entirely.
		 */
		max77779,psy-type-unknown;

		/*
		 * Per-cell profiles, copied unchanged from
		 * research/dumped.dts:6158.  The driver picks one by the
		 * battery ID it reads from the pack EEPROM through
		 * gbms_storage: this unit reports 1, selecting atl-1k, whose
		 * relaxcfg (0x083b, the second u16 of fg-params) and
		 * fg_n_regval (0xb7 = 0x2341) both match what the gauge
		 * already holds [HW 2026-09-17].  That agreement is what makes
		 * the profile safe to apply: the configuration write the
		 * driver makes at init puts back the value that is there.
		 *
		 * The model itself is not written.  A load needs
		 * model_reload >= REQUEST, and the only non-debug path to that
		 * is a POR interrupt; this gauge reports PONR=0, so the
		 * bootloader's model stays.  The profiles matter for the day
		 * it does POR, which our previous read-only driver could not
		 * have recovered from at all.
		 */
		maxim,fg-data {

			max77779,config {

				max77779,fake-255k {
					max77779,batt-id-kohm = <0xff>;
					max77779,model-version = <0x03>;
					max77779,force-reset-model-data;
					max77779,fg-model = <0x86b0ab80 0xb770b960 0xbb60bc50 0xbdf0bee0
						0xc0c0c2c0 0xc6c0ca40 0xcca0d1c0 0xd650deb0 0x200200 0x10200a00
						0x1c401030 0x1d200e00 0xfd005f0 0x6c00bd0 0x3f008f0 0x5d005d0>;
					max77779,fg-params = <0xc1b0043c 0x260e2000 0x5f00 0x7d607d6 0xc8007d6
						0xa55a2000 0xd800400 0x2800540 0x15020278 0x38700400 0x58efcea4>;
				};

				max77779,fake-170k {
					max77779,batt-id-kohm = <0xaa>;
					max77779,model-version = <0x03>;
					max77779,force-reset-model-data;
					max77779,fg-model = <0x86b0ab80 0xb770b960 0xbb60bc50 0xbdf0bee0
						0xc0c0c2c0 0xc6c0ca40 0xcca0d1c0 0xd650deb0 0x200200 0x10200a00
						0x1c401030 0x1d200e00 0xfd005f0 0x6c00bd0 0x3f008f0 0x5d005d0>;
					max77779,fg-params = <0xc1b0043c 0x260e2000 0x5f00 0x7d607d6 0xc8007d6
						0xa55a2000 0xd800400 0x2800540 0x15020278 0x38700400 0x58efcea4>;
				};

				max77779,fake-0k {
					max77779,batt-id-kohm = <0x00>;
					max77779,model-version = <0x01>;
					max77779,force-reset-model-data;
					max77779,fg-model = <0x86b0ab80 0xb770b960 0xbb60bc50 0xbdf0bee0
						0xc0c0c2c0 0xc6c0ca40 0xcca0d1c0 0xd650deb0 0x200200 0x10200a00
						0x1c401030 0x1d200e00 0xfd005f0 0x6c00bd0 0x3f008f0 0x5d005d0>;
					max77779,fg-params = <0xc1b0043c 0x260e2000 0x5f00 0x7d607d6 0xc8007d6
						0xa55a2000 0xd800400 0x2800540 0x15020278 0x38700400 0x58efcea4>;
				};

				max77779,atl-1k {
					max77779,batt-id-kohm = <0x01>;
					max77779,model-version = <0x01>;
					max77779,force-reset-model-data;
					max77779,fg-model = <0x9620ad30 0xb8a0b8e0 0xb920bb30 0xbd70be40
						0xbf60c020 0xc260c6c0 0xca60d150 0xd9a0df10 0x800170 0x332032e0
						0xe000f20 0x15400e10 0x1b700cb0 0x77007c0 0x6b006d0 0x6900690>;
					max77779,fg-params = <0xc1b0083b 0x660e4207 0x815f00 0x7fc07fc 0xc8007fc
						0xa55a3600 0x18800a01 0x78405d0 0x1c020280 0x38700400 0xc8ffcea4>;
					max77779,fg_n_regval = <0xb72341>;
					max77779,fg-aafv = <0x00 0x5f 0x0f 0x280 0x14 0x5a 0x0f 0x140 0x28 0x55
						0x0f 0x140 0x3c 0x50 0x0f 0x140 0x50 0x4b 0x0f 0x140 0x64 0x46 0x0f
						0x140>;
				};

				max77779,lwn-4k {
					max77779,batt-id-kohm = <0x04>;
					max77779,model-version = <0x01>;
					max77779,force-reset-model-data;
					max77779,fg-model = <0x91d0a3a0 0xb590b830 0xba40bbb0 0xbd40bfd0
						0xc2c0c670 0xc960cd40 0xd0f0d640 0xdb70df10 0x4000c0 0x6001010
						0x11000f00 0x14000db0 0x6c007f0 0x6c006a0 0x6e006f0 0x5400540>;
					max77779,fg-params = <0xc1b0083b 0x660e4207 0x815f00 0x8000800 0xc800800
						0xa55a390a 0x1d851002 0xb0207b0 0x22020280 0x38700400 0xc8ffcea4>;
					max77779,fg_n_regval = <0xb72341>;
					max77779,fg-aafv = <0x00 0x5f 0x0f 0x280 0x14 0x5a 0x0f 0x140 0x28 0x55
						0x0f 0x140 0x3c 0x50 0x0f 0x140 0x50 0x4b 0x0f 0x140 0x64 0x46 0x0f
						0x140>;
				};
			};
		};
	};

	/*
	 * The MAX77779's battery-backed scratchpad (research/dumped.dts:6249),
	 * as a gbms_storage provider rather than as nvmem.  It carries the tags
	 * the gauge and the battery layer keep across a reboot -- RSOC, MDLV,
	 * AAWC and the bootloader handshake.
	 *
	 * MDLV is why this cannot wait for a later step.  Nothing else serves
	 * that tag, and without it the gauge reads its stored model version as
	 * -ENOENT, decides on every boot that the version changed, force-resets
	 * the gauge and reloads the model -- then loops at 1 Hz because it
	 * cannot record the version it just wrote [HW 2026-09-17].
	 *
	 * These are the same four bytes at offset 0 that nvmem-reboot-mode used
	 * to write as the cold-reset copy of the bootloader's reboot mode:
	 * RSBM_ADDR is 0 and RS_TAG_LENGTH is 4.  Both cannot own the device,
	 * and the gauge needs this one, so that copy is gone.  The PMU
	 * SYSIP_DAT0 store still covers warm resets, which is what the test
	 * loop uses (reboot=w); after a battery pull the bootloader is entered
	 * by hand.
	 */
	sp@60 {
		compatible = "maxim,max77779sp-i2c";
		reg = <0x60>;
	};

	/*
	 * MAX77779 IF-PMIC core (research/dumped.dts:6256).  Nothing on this
	 * part reaches the AP interrupt controller directly: the fuel gauge,
	 * charger, V/I monitor and I2C master all cascade into the interrupt
	 * controller below, which is why the core has to be described before
	 * any of them can be driven by interrupt rather than by polling.
	 *
	 * The core itself is an MFD.  It instantiates its sub-devices as cells
	 * matched against the child compatibles here, so a child that is not
	 * described gets a platform device with no of_node -- harmless, and
	 * currently the case for the pin controller and the GPIO expander,
	 * which nothing consumes yet.
	 */
	max77779_pmic: pmic@66 {
		compatible = "maxim,max77779pmic-i2c";
		reg = <0x66>;

		/*
		 * The AP-facing end of the cascade.  The driver takes its own
		 * parent interrupt from the GPIO named here rather than from
		 * an "interrupts" property, so this node describes only the
		 * controller it provides to the sub-devices.
		 */
		max77779_pmic_irq: pmic-irq {
			compatible = "max77779-pmic-irq";
			max777x9,irq-gpio = <&gpa8 0 GPIO_ACTIVE_LOW>;
			interrupt-controller;
			#interrupt-cells = <2>;
			pinctrl-names = "default";
			pinctrl-0 = <&if_pmic_irq>;
		};
	};

	/*
	 * The MAX77779's main charger.  This is the first node in this stack
	 * that reaches a rail: the driver owns CHG_CNFG_00's mode field and
	 * the charge current and float voltage underneath it.
	 *
	 * Binding it writes five registers at probe, unconditionally and
	 * exactly as the vendor driver does on this silicon.  Four are
	 * protection settings: charge-over-current warn and limit go to their
	 * maximum values, CHG_CNFG_01's fast-charge safety timer is cleared,
	 * CHG_CNFG_15's watchdog is disabled, and CHG_CNFG_13's THM2
	 * connector-temperature field is zeroed -- the vendor node sets
	 * neither google,max77779-thm2-monitor nor max77779,usb-mon, so it
	 * takes the same branch.  Measured against the documented reset values
	 * only the safety timer is actually a relaxation: the watchdog and
	 * THM2's hardware-control bit are already off, and the maxed COP
	 * thresholds arm a protection whose enable bit nothing here ever sets.
	 * These registers are OTP-shadowed, so what the part powers up with is
	 * not necessarily what the datasheet reset says.
	 *
	 * The fifth is a current limit.  The DC_ICL votable is created with
	 * gvotable_use_default(), which runs an election immediately, so
	 * CHG_CNFG_10's wireless input limit is written to the vendor's
	 * 700 mA default.  The receiver is fitted but not described here, so
	 * that rail is only reached with a pad under the phone.
	 *
	 * The vendor relaxes what it relaxes because its battery and charger
	 * layers put profile-driven limits back in their place, and those
	 * layers are not here yet -- so until they are, this is knowingly less
	 * protection than the part ships with.  The JEITA and thermistor
	 * protection is the backstop either way: no driver configures it, the
	 * thresholds come from OTP, and nothing in this port can switch it off.
	 *
	 * No charging mode is written.  That probe-time election does reach
	 * the mode votable -- the DC_ICL callback casts a disabled WLCIN_OFF
	 * ballot -- but max77779_mode_callback() accumulates its decision by
	 * walking ballots and skipping disabled ones, so with no enabled
	 * ballot anywhere its state stays empty, it takes the "nope" path and
	 * CHG_CNFG_00 is left alone.  That holds for any election while
	 * nothing votes, which is a stronger guarantee than the default merely
	 * not running.  The use-case state machine that arranges buck, boost,
	 * OTG and wireless-transmit modes is reached only from a mode vote,
	 * and its device-tree lookup is lazy -- probe passes a NULL node
	 * deliberately.
	 *
	 * Note what the power supply this registers exposes.  ONLINE and
	 * CURRENT_MAX are writable, and here they only go one way: writing
	 * either to 0 casts an enabled ballot that turns CHG_CNFG_00 off, and
	 * retracting it leaves the register off, because nothing in this port
	 * votes a buck mode back on.  CHG_CNFG_00 is OTP-reset, so a warm
	 * reset need not restore it.
	 *
	 * Four groups of the vendor node's properties are dropped, all of them
	 * naming hardware this board does not describe:
	 *
	 *   - wlc-en and wlc-spoof are GPIOs inside the P9222 wireless
	 *     receiver, and extbst-ctl is one inside the RT9471 buck charger.
	 *     Neither driver is here, so the phandles have no target.  A
	 *     missing property reads back as a negative GPIO rather than
	 *     -EPROBE_DEFER, which is what the use-case code treats as "not
	 *     fitted"; a property pointing at an absent provider would instead
	 *     defer forever.
	 *   - wlc-spoof-vbyp and wlc_notify_charge_disable belong to the same
	 *     wireless path.
	 *   - rx-to-rx-otg-en and ext-otg-only describe OTG through that
	 *     external boost.  The connector here is sink and device only with
	 *     PD disabled, so no OTG use case is reachable to begin with.
	 *   - chg-term-voltage is dead in the vendor tree too: this driver
	 *     version never reads it, taking the termination voltage from the
	 *     charger layer instead.
	 *
	 * The GPIO child and the interrupt-controller properties are kept
	 * because the driver registers both providers against this node
	 * regardless of what consumes them.
	 */
	chrg@69 {
		compatible = "maxim,max77779chrg-i2c";
		reg = <0x69>;
		max77779,psy-name = "main-charger";
		max77779,pmic = <&max77779_pmic>;
		interrupt-parent = <&max77779_pmic_irq>;
		interrupts = <2 IRQ_TYPE_LEVEL_LOW>;
		interrupt-controller;
		#interrupt-cells = <2>;
		max77779,wcin-inlim-headroom = <40000>;

		max77779_gpio {
			gpio-controller;
			#gpio-cells = <2>;
			ngpios = <1>;
		};
	};
};

&usb32drd {
	orientation-switch;

	port {
		usb32drd_orien_sw: endpoint {
			remote-endpoint = <&usbc0_orien_sw>;
		};
	};
};

&usb_dwc3 {
	dr_mode = "otg";
	usb-role-switch;
	role-switch-default-mode = "peripheral";

	port {
		usb_dwc3_role_sw: endpoint {
			remote-endpoint = <&usbc0_role_sw>;
		};
	};
};

/*
 * USI9 in I2C mode: the eUSB2 repeater at 0x3e, NFC at 0x08 and the
 * cs40l26a haptics codec at 0x43.
 *
 * No child nodes yet, deliberately.  The repeater is the reason this bus is
 * enabled -- it converts eUSB2 signalling to USB2 levels at the connector, and
 * nothing in mainline has ever programmed it -- but there is no driver for it
 * yet, and instantiating a client at 0x3e would make i2c-dev refuse the address
 * with -EBUSY.  Leaving the address unclaimed keeps it reachable from
 * userspace, which is how the repeater's registers get characterised before a
 * driver is written.
 */
&usi9 {
	samsung,mode = <USI_MODE_I2C>;
	status = "okay";
};

&hsi2c_9 {
	status = "okay";
};

&usi10 {
	samsung,mode = <USI_MODE_I2C>;
	status = "okay";
};

&hsi2c_10 {
	status = "okay";

	/*
	 * Battery pack ID EEPROM (downstream battery_pack_eeprom), writable as
	 * downstream has it.  The gauge saves its model state here (GMSR) and
	 * records the pack's cycle count, and both fail with -ETIMEDOUT against
	 * a read-only at24 [HW 2026-09-17].
	 *
	 * This holds the pairing and health history the Android slot reads too,
	 * so what keeps it safe is no longer that the driver cannot write: it
	 * is that gbms_lotr_update() reaches neither of its destructive layout
	 * migrations while the google_bms node omits "google,lotr-version".
	 * See the comment there.
	 */
	battery_pack_eeprom: eeprom@50 {
		compatible = "atmel,24c08";
		reg = <0x50>;
	};
};

&usi4_hsi0 {
	samsung,mode = <USI_MODE_I2C>;
	status = "okay";
};

/*
 * Speaker amplifiers: two TI TAS2572 dies, one per speaker.  Downstream
 * models them as a single ti,tas25xx node fronting both I2C addresses
 * (research/dumped.dts:6833, zumapro-tegu-audio-common-tas2572.dtsi); the
 * mainline tas2781 driver supports the TAS2572 in register mode with no
 * DSP firmware, but takes one reset/IRQ line per node, so each die gets
 * its own node.  Reset and IRQ GPIOs are from the dumped ti,reset-gpio(2)/
 * ti,irq-gpio(2) properties.  The amps are wired to the AoC TDM0 backend;
 * they only make sound once the AoC sound card exists, but they probe and
 * expose regmap/controls standalone.
 */
&hsi2c_19 {
	status = "okay";
	clock-frequency = <400000>;

	speaker_amp_l: amplifier@48 {
		compatible = "ti,tas2572";
		reg = <0x48>;
		#sound-dai-cells = <0>;
		reset-gpios = <&gpp6 3 GPIO_ACTIVE_HIGH>;
		interrupts-extended = <&gpa5 5 IRQ_TYPE_LEVEL_LOW>;
		pinctrl-names = "default";
		pinctrl-0 = <&spk_amp_l_irq &spk_amp_l_rst>;
		sound-name-prefix = "L";
	};

	speaker_amp_r: amplifier@49 {
		compatible = "ti,tas2572";
		reg = <0x49>;
		#sound-dai-cells = <0>;
		reset-gpios = <&gph2 1 GPIO_ACTIVE_HIGH>;
		interrupts-extended = <&gpa7 2 IRQ_TYPE_LEVEL_LOW>;
		pinctrl-names = "default";
		pinctrl-0 = <&spk_amp_r_irq &spk_amp_r_rst>;
		sound-name-prefix = "R";
	};
};

/*
 * AoC sound card.  The AoC firmware is the audio DSP/router: frontends are
 * AoC ring-buffer services (audio_playbackN), the backend is the AoC TDM0
 * interface feeding the two TAS2572 dies.  Structure and IDs follow the
 * dumped downstream card (research/dumped.dts sound-aoc node); the id
 * property is the AoC entrypoint/backend ID consumed by google-aoc-path.
 *
 * The dai_link order is load-bearing: PCM device numbers follow link
 * order, and the driver's device-number -> stream-type/entrypoint tables
 * (aoc_audio_stream_type[], aoc_alsa_hw.c) assume the downstream numbering
 * (device 0 = EP1 = the mmap stream, device 1 = EP2 = stock primary,
 * device 5 = EP6 = deep buffer, device 8 = the first capture frontend).
 * Capture therefore has to sit at device 8, so the compress (device 6) and
 * haptics (device 7) frontends occupy their slots first even though their
 * backends (compress sub-driver / cs40l26) are not brought up yet; opening
 * those two PCMs fails cleanly until then.  The backends come last.  Extend
 * this list, never reorder it.
 */
/ {
	aoc_pcm: aoc-pcm {
		compatible = "google-aoc-snd-pcm";
	};

	aoc_voice: aoc-voice {
		compatible = "google-aoc-snd-voice";
	};

	aoc_path: aoc-path {
		compatible = "google-aoc-path";
		#sound-dai-cells = <1>;
	};

	sound-aoc {
		compatible = "google-aoc-snd-card";
		aoc-card-name = "google,aoc-snd-card";

		dai_link {
			fe_ep1_rx {
				dai-name = "audio_playback0";
				stream-name = "EP1 playback";
				id = <0x00>;
				dynamic;
				playback;

				cpu {
					sound-dai = <&aoc_path 0x00>;
				};

				platform {
					rx1 {
						of_drv = <&aoc_pcm>;
					};
				};
			};

			fe_ep2_rx {
				dai-name = "audio_playback1";
				stream-name = "EP2 playback";
				id = <0x01>;
				dynamic;
				playback;

				cpu {
					sound-dai = <&aoc_path 0x01>;
				};

				platform {
					rx1 {
						of_drv = <&aoc_pcm>;
					};
				};
			};

			fe_ep3_rx {
				dai-name = "audio_playback2";
				stream-name = "EP3 playback";
				id = <0x02>;
				dynamic;
				playback;

				cpu {
					sound-dai = <&aoc_path 0x02>;
				};

				platform {
					rx1 {
						of_drv = <&aoc_pcm>;
					};
				};
			};

			fe_ep4_rx {
				dai-name = "audio_playback3";
				stream-name = "EP4 playback";
				id = <0x03>;
				dynamic;
				playback;

				cpu {
					sound-dai = <&aoc_path 0x03>;
				};

				platform {
					rx1 {
						of_drv = <&aoc_pcm>;
					};
				};
			};

			/*
			 * Device 4 (EP5) is the telephony frontend: downstream
			 * binds it to google-aoc-snd-voice (dumped.dts of_drv
			 * 0x206), and aoc_alsa_hw.c prepare_phonecall() gates on
			 * pcm->device == 4.  Route it through aoc_voice so opening
			 * this PCM issues CMD_AUDIO_OUTPUT_TELEPHONY_MODEM_START
			 * to bind modem<->AoC call audio.
			 */
			fe_ep5_rx {
				dai-name = "audio_playback4";
				stream-name = "EP5 playback";
				id = <0x04>;
				dynamic;
				playback;

				cpu {
					sound-dai = <&aoc_path 0x04>;
				};

				platform {
					rx1 {
						of_drv = <&aoc_voice>;
					};
				};
			};

			fe_ep6_rx {
				dai-name = "audio_playback5";
				stream-name = "EP6 playback";
				id = <0x05>;
				dynamic;
				playback;

				cpu {
					sound-dai = <&aoc_path 0x05>;
				};

				platform {
					rx1 {
						of_drv = <&aoc_pcm>;
					};
				};
			};

			/*
			 * Device 6/7 slot-holders: they claim the compress and
			 * haptics device numbers so the capture frontend lands
			 * on device 8.  Their backends are not wired yet, so the
			 * PCMs exist but fail to start until compress/cs40l26
			 * bring-up.
			 */
			fe_ep7_rx {
				dai-name = "audio_playback6";
				stream-name = "EP7 playback";
				id = <0x06>;
				dynamic;
				playback;

				cpu {
					sound-dai = <&aoc_path 0x06>;
				};

				platform {
					rx1 {
						of_drv = <&aoc_pcm>;
					};
				};
			};

			fe_ep8_rx {
				dai-name = "audio_haptics";
				stream-name = "EP8 playback";
				id = <0x07>;
				dynamic;
				playback;

				cpu {
					sound-dai = <&aoc_path 0x07>;
				};

				platform {
					rx1 {
						of_drv = <&aoc_pcm>;
					};
				};
			};

			/* Device 8: first capture frontend (audio-record). */
			fe_ep1_tx {
				dai-name = "audio_capture0";
				stream-name = "EP1 capture";
				id = <0x40000000>;
				dynamic;
				capture;

				cpu {
					sound-dai = <&aoc_path 0x40000000>;
				};

				platform {
					tx1 {
						of_drv = <&aoc_pcm>;
					};
				};
			};

			/*
			 * Devices 9-11: EP2/EP3 capture placeholders (like the
			 * compress/haptics playback slots) so the voice-call
			 * capture frontend lands at device 11 = NORMAL in
			 * aoc_audio_stream_type[], matching downstream
			 * audio_capture1..3.  EP4 capture (id 0x40000003) is the
			 * telephony *uplink*: aoc_audio_path_open() opens the
			 * phone-call capture path for src_idx == 3, which starts
			 * the modem mic input (aoc_telephony_mic_open); it binds
			 * to google-aoc-snd-voice like the downlink FE.  EP2/EP3
			 * open cleanly-fail until their subsystems come up.
			 */
			fe_ep2_tx {
				dai-name = "audio_capture1";
				stream-name = "EP2 capture";
				id = <0x40000001>;
				dynamic;
				capture;

				cpu {
					sound-dai = <&aoc_path 0x40000001>;
				};

				platform {
					tx1 {
						of_drv = <&aoc_pcm>;
					};
				};
			};

			fe_ep3_tx {
				dai-name = "audio_capture2";
				stream-name = "EP3 capture";
				id = <0x40000002>;
				dynamic;
				capture;

				cpu {
					sound-dai = <&aoc_path 0x40000002>;
				};

				platform {
					tx1 {
						of_drv = <&aoc_pcm>;
					};
				};
			};

			fe_ep4_tx {
				dai-name = "audio_capture3";
				stream-name = "EP4 capture";
				id = <0x40000003>;
				dynamic;
				capture;

				cpu {
					sound-dai = <&aoc_path 0x40000003>;
				};

				platform {
					tx1 {
						of_drv = <&aoc_voice>;
					};
				};
			};

			be_tdm0_rx {
				dai-name = "TDM_0_RX Playback";
				stream-name = "TDM_0_RX Playback";
				id = <0x80000006>;
				playback;
				no-pcm;
				useops;
				usefixup;

				cpu {
					sound-dai = <&aoc_path 0x80000006>;
				};

				daifmt {
					dai-format = "dsp_a";
				};

				codec {
					sound-dai = <&speaker_amp_l>, <&speaker_amp_r>;
				};
			};

			/*
			 * Capture backend.  The built-in mics are DMICs owned by
			 * the AoC, so there is no AP-side codec: the link takes
			 * the dummy codec and the AoC sources the samples.  The
			 * capture frontend routes here via the "INTERNAL_MIC_TX"
			 * mixer switch on the EP1_TX path.
			 */
			be_internal_mic_tx {
				dai-name = "INTERNAL_MIC_TX Capture";
				stream-name = "INTERNAL_MIC_TX Capture";
				id = <0xc000000a>;
				capture;
				no-pcm;
				useops;
				usefixup;

				cpu {
					sound-dai = <&aoc_path 0xc000000a>;
				};
			};
		};
	};
};

/*
 * PCIe GEN3A_1 root complex for the on-board Broadcom BCM4383 WiFi.
 *
 * Pin wiring is from research/dumped.dts:4714-4750: PERST# on gph3-0
 * (active low, driven by the controller), CLKREQ# on gph3-1 (special
 * function 2, pull-up), and WL_REG_ON on gph3-4.  The WiFi chip is the
 * PCIe link partner, so it must be powered for the link to train; until a
 * WiFi driver owns WL_REG_ON, a GPIO hog holds it asserted from boot so
 * the endpoint enumerates.
 */
/*
 * gph3/gph4 live on the HSI2 GPIO pin controller (pinctrl_hsi1, 0x13040000),
 * which the minimal tree leaves disabled.  Enable it so the PCIe PERST#,
 * CLKREQ# and WL_REG_ON lines on gph3 are usable.
 */
&pinctrl_hsi1 {
	status = "okay";

	pcie1_clkreq: pcie1-clkreq-pins {
		samsung,pins = "gph3-1";
		samsung,pin-function = <ZUMAPRO_PIN_FUNC_2>;
		samsung,pin-pud = <ZUMAPRO_PIN_PULL_UP>;
		samsung,pin-drv = <ZUMAPRO_PIN_DRV_X3>;
		samsung,pin-con-pdn = <ZUMAPRO_PIN_CON_PDN_PREV>;
		samsung,pin-pud-pdn = <ZUMAPRO_PIN_PULL_UP>;
	};

	pcie1_perst: pcie1-perst-pins {
		samsung,pins = "gph3-0";
		samsung,pin-function = <ZUMAPRO_PIN_FUNC_OUTPUT>;
		samsung,pin-drv = <ZUMAPRO_PIN_DRV_X4>;
		samsung,pin-con-pdn = <ZUMAPRO_PIN_CON_PDN_PREV>;
	};

	/*
	 * WL_REG_ON (gph3-4) is the BCM4383's enable.  A pad with no CON_PDN
	 * of its own does not retain its level in SYS_SLEEP, so the enable
	 * stops being driven and the chip loses power -- it then returns from
	 * every deep suspend with no firmware and brcmfmac re-downloads it.
	 * PERST# and CLKREQ# above already retain; this is the third pin of
	 * the same group, and downstream sets it the same way in cfg_wlanen
	 * (research/dumped.dts:4732), off the same PCIe RC node.
	 *
	 * samsung,pin-function is deliberately omitted so that wlan_reg_on_hog
	 * stays the only writer of this pin's CON and DAT fields; the group
	 * then applies as pinconf alone, touching PUD, CON_PDN and PUD_PDN,
	 * which is the powerdown retention a gpio-hog cannot express.
	 */
	wlan_reg_on: wlan-reg-on-pins {
		samsung,pins = "gph3-4";
		samsung,pin-pud = <ZUMAPRO_PIN_PULL_NONE>;
		samsung,pin-con-pdn = <ZUMAPRO_PIN_CON_PDN_PREV>;
		samsung,pin-pud-pdn = <ZUMAPRO_PIN_PULL_NONE>;
	};
};

&gph3 {
	wlan_reg_on_hog: wlan-reg-on-hog {
		gpio-hog;
		gpios = <4 GPIO_ACTIVE_HIGH>;
		output-high;
		line-name = "wlan-reg-on";
	};
};

/*
 * PCIe CH0 (HSI1): the Exynos Modem 5300.  PERST# is gph0-0 and CLKREQ# is
 * gph0-1 (special function 2, pull-up) on the HSI1 GPIO pin controller at
 * 0x12040000 (labelled pinctrl_hsi0 in this tree), from
 * research/dumped.dts:4549-4565.  The CP rail-sequencing lines below are from
 * the downstream cpif node (research/dumped.dts:20622-20632); they carry raw
 * levels, so all are GPIO_ACTIVE_HIGH and the RC's bring-up stub writes the
 * downstream values verbatim.
 *
 * The link is capped at Gen1 x1 for bring-up: downstream also trains the
 * first boot-time link at GEN1 x1 (s5100_poweron_pcie(boot_on)) and only
 * moves to Gen3 x2 with the link bounce after the boot-image download, which
 * needs the modem driver.
 */
&pinctrl_hsi0 {
	status = "okay";

	pcie0_clkreq: pcie0-clkreq-pins {
		samsung,pins = "gph0-1";
		samsung,pin-function = <ZUMAPRO_PIN_FUNC_2>;
		samsung,pin-pud = <ZUMAPRO_PIN_PULL_UP>;
		samsung,pin-drv = <ZUMAPRO_PIN_DRV_X4>;
		samsung,pin-con-pdn = <ZUMAPRO_PIN_CON_PDN_PREV>;
		samsung,pin-pud-pdn = <ZUMAPRO_PIN_PULL_UP>;
	};

	pcie0_perst: pcie0-perst-pins {
		samsung,pins = "gph0-0";
		samsung,pin-function = <ZUMAPRO_PIN_FUNC_OUTPUT>;
		samsung,pin-drv = <ZUMAPRO_PIN_DRV_X4>;
		samsung,pin-con-pdn = <ZUMAPRO_PIN_CON_PDN_PREV>;
	};

	/* Right speaker amp reset (downstream tas2572_2_rst). */
	spk_amp_r_rst: spk-amp-r-rst-pins {
		samsung,pins = "gph2-1";
		samsung,pin-function = <ZUMAPRO_PIN_FUNC_OUTPUT>;
		samsung,pin-pud = <ZUMAPRO_PIN_PULL_NONE>;
	};
};

&pcie0_phy {
	status = "okay";
};

&pcie0 {
	pinctrl-names = "default";
	pinctrl-0 = <&pcie0_clkreq &pcie0_perst &modem_ap2cp_ctrl
		     &modem_ap2cp_pm_wrst>;
	reset-gpios = <&gph0 0 GPIO_ACTIVE_LOW>;
	num-lanes = <1>;
	max-link-speed = <1>;
	google,cp-pwr-gpios = <&gpp12 2 GPIO_ACTIVE_HIGH>;
	google,cp-nreset-gpios = <&gpp12 3 GPIO_ACTIVE_HIGH>;
	google,cp-pm-wrst-gpios = <&gpp8 3 GPIO_ACTIVE_HIGH>;
	google,cp-wrst-gpios = <&gpp16 3 GPIO_ACTIVE_HIGH>;
	google,cp-wakeup-gpios = <&gpp16 0 GPIO_ACTIVE_HIGH>;
	google,cp-pda-active-gpios = <&gpp16 2 GPIO_ACTIVE_HIGH>;
	/*
	 * Source: dumped.dts gpio_ap2cp_dump_noti (gpp16-1).  Downstream
	 * power_on_cp() drives it low before the rails; left floating, CP MAIN
	 * may boot into dump mode instead of normal IPC.
	 */
	google,cp-dump-noti-gpios = <&gpp16 1 GPIO_ACTIVE_HIGH>;
	status = "okay";
};

/*
 * Exynos Modem 5300 boot control.  Consumes the endpoint the CH0 RC
 * enumerates: stages the first-stage CP bootloader in cp_rmem, points the
 * RC's MSI target at cp_msi_rmem (the mask ROM reports boot progress above
 * that address) and runs the shared-memory handshake to CP ONLINE.  The
 * doorbell bus address and the CP2AP_WAKEUP line (gpa5-1) are from the
 * downstream cpif node (research/dumped.dts:20516, 20632).
 */
/ {
	/*
	 * Touch Bus Negotiator.  tbn,mode = 2 (TBN_MODE_AOC_CHANNEL): the
	 * AP <-> AoC bus handshake runs as messages over the com.google.tbn
	 * AoC service, not over GPIOs.  Matches research/dumped.dts, which
	 * carries a bare /tbn node with tbn,mode = 2 and no GPIOs.
	 * tbn,max_devices defaults to 1 (single touch consumer).
	 */
	tbn {
		compatible = "touch_bus_negotiator";
		tbn,mode = <2>;
		tbn,max_devices = <1>;
	};

	/*
	 * Wake gestures watched by the AoC while the AP sleeps: a single tap
	 * on the powered-down panel, and lift-to-wake.  There is no hardware
	 * here to describe -- the sensors live in AoC firmware and are reached
	 * over the com.google.usf AOCC service -- but the driver has to know
	 * which panel it follows, since the gestures are armed only while that
	 * panel is off.
	 */
	aoc-gesture-wake {
		compatible = "google,aoc-gesture-wake";
		panel = <&panel>;
	};

	modem {
		compatible = "samsung,s5300-modem";
		pinctrl-names = "default";
		pinctrl-0 = <&modem_cp2ap_ps_hold &modem_cp2ap_wakeup
			     &modem_cp2ap_active &modem_cp2ap_wrst>;
		memory-region = <&cp_rmem_reserved>, <&cp_msi_rmem_reserved>,
				<&cp_rmem_1_reserved>;
		memory-region-names = "ipc", "msi", "pktproc";
		firmware-name = "tegu/cp_pbl.bin";
		google,pcie = <&pcie0>;
		samsung,doorbell-addr = <0x14e60000>;
		cp2ap-wakeup-gpios = <&gpa5 1 GPIO_ACTIVE_HIGH>;
		/*
		 * Optional CP-aliveness inputs, read only to classify a runtime
		 * link wedge: CP_ACTIVE (gpa5-2) is the CP firmware heartbeat
		 * (low = crash), PS_HOLD (gpa5-0) is the CP power-rail hold
		 * (low = the CP powered its own rail off).  gpa5-{0,2} from the
		 * downstream cpif node (gpio_cp2ap_cp_ps_hold,
		 * gpio_cp2ap_phone_active).
		 */
		cp2ap-active-gpios = <&gpa5 2 GPIO_ACTIVE_HIGH>;
		cp2ap-ps-hold-gpios = <&gpa5 0 GPIO_ACTIVE_HIGH>;
	};
};

&pcie_phy {
	status = "okay";
};

&pcie {
	pinctrl-names = "default";
	pinctrl-0 = <&pcie1_clkreq &pcie1_perst &wlan_reg_on>;
	reset-gpios = <&gph3 0 GPIO_ACTIVE_LOW>;
	status = "okay";

	/*
	 * Describe the on-board BCM4383 endpoint (bus 1, device 0) behind the
	 * root port (bus 0, device 0) so brcmfmac gets an of_node and runs its
	 * MAC-address path.  The per-device WLAN MAC is not in the chip; the
	 * bootloader publishes it in /chosen/config/wlan_mac1, which brcmfmac
	 * reads as a fallback (see brcmfmac of.c).
	 */
	pci@0,0 {
		device_type = "pci";
		reg = <0x0 0x0 0x0 0x0 0x0>;
		#address-cells = <3>;
		#size-cells = <2>;
		bus-range = <0x01 0x01>;
		ranges;

		wifi@0,0 {
			compatible = "pci14e4,4449", "brcm,bcm4329-fmac";
			reg = <0x10000 0x0 0x0 0x0 0x0>;

			/*
			 * OOB host-wake: the BCM4383 pulses gpa5-3 when it has
			 * traffic for the host while the PCIe link is in a deep
			 * runtime-PM state that cannot deliver an in-band MSI.
			 */
			interrupts-extended = <&gpa5 3 IRQ_TYPE_EDGE_RISING>;
			interrupt-names = "host-wake";
			pinctrl-names = "default";
			pinctrl-0 = <&wlan_host_wake>;
		};
	};
};

&bts {
	status = "okay";
};

/* MFC firmware bring-up uses the board's standard IOVA reservation. */
&pd_mfc {
	status = "okay";
};

&cmu_mfc {
	status = "okay";
};

&sysreg_mfc {
	status = "okay";
};

&sysmmu_mfc {
	status = "okay";
};

&s2mpu_mfc {
	status = "okay";
};

/* USB DMA passes the HSI0 S2MPU, which resets to blocking with the domain. */
&s2mpu_hsi0 {
	status = "okay";
};

&mfc {
	memory-region = <&mfc_firmware_iova>;
	status = "okay";
};
